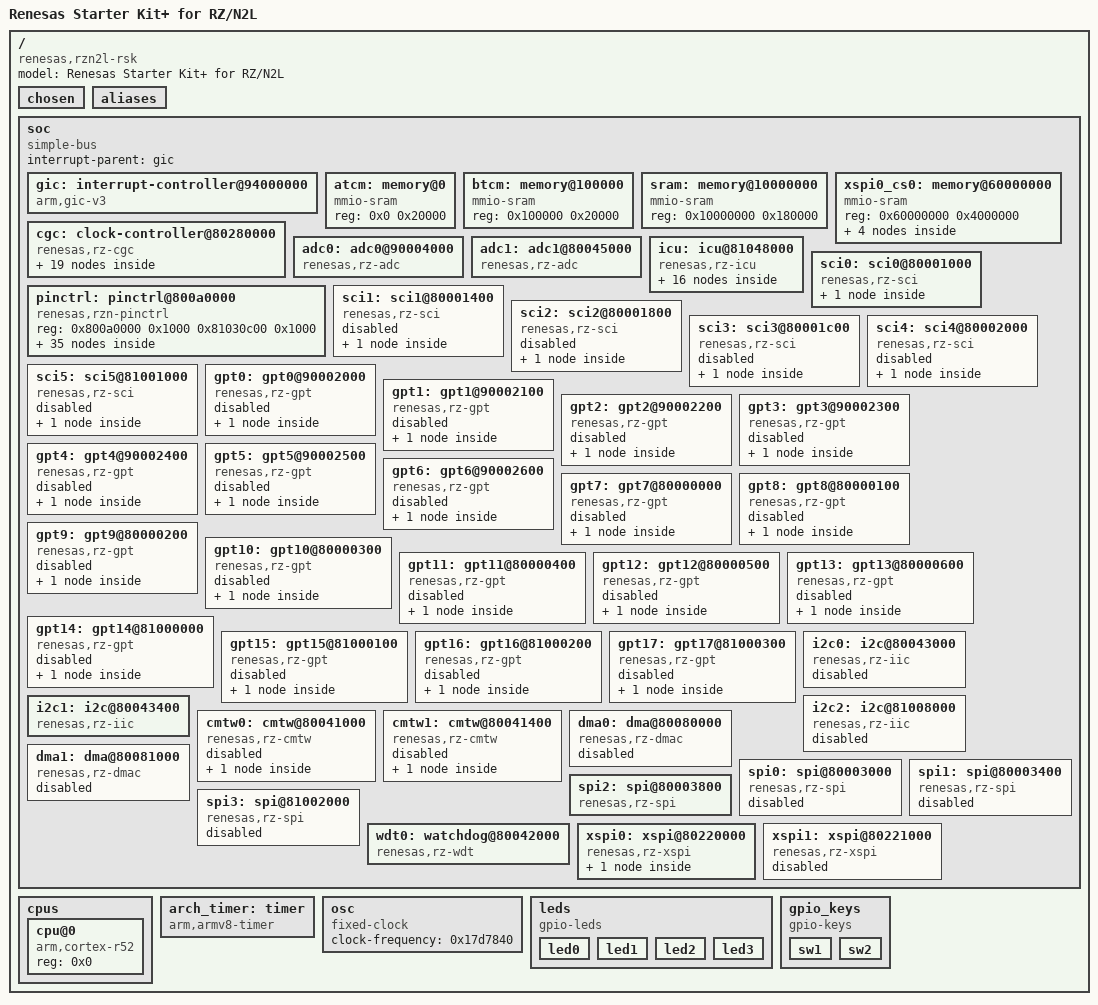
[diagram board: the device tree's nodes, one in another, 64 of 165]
/dts-v1/;

/* node '/' defined in zephyr/dts/common/skeleton.dtsi:9 */
/ {
	#address-cells = < 0x1 >;                  /* in zephyr/dts/arm/renesas/rz/rzn/r9a07g084.dtsi:16 */
	#size-cells = < 0x1 >;                     /* in zephyr/dts/arm/renesas/rz/rzn/r9a07g084.dtsi:17 */
	model = "Renesas Starter Kit+ for RZ/N2L"; /* in zephyr/boards/renesas/rzn2l_rsk/rzn2l_rsk.dts:12 */
	compatible = "renesas,rzn2l-rsk";          /* in zephyr/boards/renesas/rzn2l_rsk/rzn2l_rsk.dts:13 */

	/* node '/chosen' defined in zephyr/dts/common/skeleton.dtsi:13 */
	chosen {
		zephyr,sram = &atcm;                      /* in zephyr/boards/renesas/rzn2l_rsk/rzn2l_rsk.dts:16 */
		zephyr,flash = &mx25u51245g;              /* in zephyr/boards/renesas/rzn2l_rsk/rzn2l_rsk.dts:17 */
		zephyr,code-partition = &slot0_partition; /* in zephyr/boards/renesas/rzn2l_rsk/rzn2l_rsk.dts:18 */
		zephyr,console = &uart0;                  /* in zephyr/boards/renesas/rzn2l_rsk/rzn2l_rsk.dts:19 */
		zephyr,shell-uart = &uart0;               /* in zephyr/boards/renesas/rzn2l_rsk/rzn2l_rsk.dts:20 */
	};

	/* node '/aliases' defined in zephyr/dts/common/skeleton.dtsi:15 */
	aliases {
		led0 = &led0;      /* in zephyr/boards/renesas/rzn2l_rsk/rzn2l_rsk.dts:24 */
		led1 = &led1;      /* in zephyr/boards/renesas/rzn2l_rsk/rzn2l_rsk.dts:25 */
		sw0 = &sw1;        /* in zephyr/boards/renesas/rzn2l_rsk/rzn2l_rsk.dts:26 */
		watchdog0 = &wdt0; /* in zephyr/boards/renesas/rzn2l_rsk/rzn2l_rsk.dts:27 */
	};

	/* node '/soc' defined in zephyr/dts/arm/armv8-r.dtsi:10 */
	soc {
		#address-cells = < 0x1 >;    /* in zephyr/dts/arm/armv8-r.dtsi:11 */
		#size-cells = < 0x1 >;       /* in zephyr/dts/arm/armv8-r.dtsi:12 */
		compatible = "simple-bus";   /* in zephyr/dts/arm/armv8-r.dtsi:13 */
		ranges;                      /* in zephyr/dts/arm/armv8-r.dtsi:14 */
		interrupt-parent = < &gic >; /* in zephyr/dts/arm/renesas/rz/rzn/r9a07g084.dtsi:47 */

		/* node '/soc/interrupt-controller@94000000' defined in zephyr/dts/arm/renesas/rz/rzn/r9a07g084.dtsi:49 */
		gic: interrupt-controller@94000000 {
			compatible = "arm,gic-v3",
			             "arm,gic";       /* in zephyr/dts/arm/renesas/rz/rzn/r9a07g084.dtsi:50 */
			reg = < 0x94000000 0x10000 >,
			      < 0x94100000 0x80000 >; /* in zephyr/dts/arm/renesas/rz/rzn/r9a07g084.dtsi:51 */
			interrupt-controller;         /* in zephyr/dts/arm/renesas/rz/rzn/r9a07g084.dtsi:53 */
			#interrupt-cells = < 0x4 >;   /* in zephyr/dts/arm/renesas/rz/rzn/r9a07g084.dtsi:54 */
			status = "okay";              /* in zephyr/dts/arm/renesas/rz/rzn/r9a07g084.dtsi:55 */
			phandle = < 0x1 >;            /* in zephyr/dts/arm/renesas/rz/rzn/r9a07g084.dtsi:47 */
		};

		/* node '/soc/memory@0' defined in zephyr/dts/arm/renesas/rz/rzn/r9a07g084.dtsi:58 */
		atcm: memory@0 {
			compatible = "mmio-sram"; /* in zephyr/dts/arm/renesas/rz/rzn/r9a07g084.dtsi:59 */
			reg = < 0x0 0x20000 >;    /* in zephyr/dts/arm/renesas/rz/rzn/r9a07g084.dtsi:60 */
		};

		/* node '/soc/memory@100000' defined in zephyr/dts/arm/renesas/rz/rzn/r9a07g084.dtsi:63 */
		btcm: memory@100000 {
			compatible = "mmio-sram";   /* in zephyr/dts/arm/renesas/rz/rzn/r9a07g084.dtsi:64 */
			reg = < 0x100000 0x20000 >; /* in zephyr/dts/arm/renesas/rz/rzn/r9a07g084.dtsi:65 */
		};

		/* node '/soc/memory@10000000' defined in zephyr/dts/arm/renesas/rz/rzn/r9a07g084.dtsi:68 */
		sram: memory@10000000 {
			compatible = "mmio-sram";      /* in zephyr/dts/arm/renesas/rz/rzn/r9a07g084.dtsi:69 */
			reg = < 0x10000000 0x180000 >; /* in zephyr/dts/arm/renesas/rz/rzn/r9a07g084.dtsi:70 */
		};

		/* node '/soc/memory@60000000' defined in zephyr/dts/arm/renesas/rz/rzn/r9a07g084.dtsi:73 */
		xspi0_cs0: memory@60000000 {
			compatible = "mmio-sram";       /* in zephyr/dts/arm/renesas/rz/rzn/r9a07g084.dtsi:74 */
			reg = < 0x60000000 0x4000000 >; /* in zephyr/dts/arm/renesas/rz/rzn/r9a07g084.dtsi:75 */

			/* node '/soc/memory@60000000/partitions' defined in zephyr/dts/arm/renesas/rz/rzn/r9a07g084.dtsi:77 */
			partitions {
				compatible = "fixed-partitions"; /* in zephyr/dts/arm/renesas/rz/rzn/r9a07g084.dtsi:78 */
				#address-cells = < 0x1 >;        /* in zephyr/dts/arm/renesas/rz/rzn/r9a07g084.dtsi:79 */
				#size-cells = < 0x1 >;           /* in zephyr/dts/arm/renesas/rz/rzn/r9a07g084.dtsi:80 */

				/* node '/soc/memory@60000000/partitions/partition@0' defined in zephyr/dts/arm/renesas/rz/rzn/r9a07g084.dtsi:82 */
				loader_param: partition@0 {
					label = "loader-param"; /* in zephyr/dts/arm/renesas/rz/rzn/r9a07g084.dtsi:83 */
					reg = < 0x0 0x4c >;     /* in zephyr/dts/arm/renesas/rz/rzn/r9a07g084.dtsi:84 */
					read-only;              /* in zephyr/dts/arm/renesas/rz/rzn/r9a07g084.dtsi:85 */
				};

				/* node '/soc/memory@60000000/partitions/partition@4C' defined in zephyr/dts/arm/renesas/rz/rzn/r9a07g084.dtsi:88 */
				loader_program: partition@4C {
					label = "loader-program"; /* in zephyr/dts/arm/renesas/rz/rzn/r9a07g084.dtsi:89 */
					reg = < 0x4c 0xdfb4 >;    /* in zephyr/dts/arm/renesas/rz/rzn/r9a07g084.dtsi:90 */
					read-only;                /* in zephyr/dts/arm/renesas/rz/rzn/r9a07g084.dtsi:91 */
				};

				/* node '/soc/memory@60000000/partitions/partition@E000' defined in zephyr/dts/arm/renesas/rz/rzn/r9a07g084.dtsi:94 */
				slot0_partition: partition@E000 {
					label = "image-0";          /* in zephyr/dts/arm/renesas/rz/rzn/r9a07g084.dtsi:95 */
					reg = < 0xe000 0x3ff2000 >; /* in zephyr/dts/arm/renesas/rz/rzn/r9a07g084.dtsi:96 */
					read-only;                  /* in zephyr/dts/arm/renesas/rz/rzn/r9a07g084.dtsi:97 */
				};
			};
		};

		/* node '/soc/clock-controller@80280000' defined in zephyr/dts/arm/renesas/rz/rzn/r9a07g084.dtsi:102 */
		cgc: clock-controller@80280000 {
			compatible = "renesas,rz-cgc"; /* in zephyr/dts/arm/renesas/rz/rzn/r9a07g084.dtsi:103 */
			reg = < 0x80280000 0x314 >,
			      < 0x81280000 0x324 >;    /* in zephyr/dts/arm/renesas/rz/rzn/r9a07g084.dtsi:104 */
			clocks = < &osc >;             /* in zephyr/dts/arm/renesas/rz/rzn/r9a07g084.dtsi:105 */
			#clock-cells = < 0x1 >;        /* in zephyr/dts/arm/renesas/rz/rzn/r9a07g084.dtsi:106 */
			status = "okay";               /* in zephyr/dts/arm/renesas/rz/rzn/r9a07g084.dtsi:107 */

			/* node '/soc/clock-controller@80280000/loco' defined in zephyr/dts/arm/renesas/rz/rzn/r9a07g084.dtsi:109 */
			loco: loco {
				compatible = "fixed-clock";    /* in zephyr/dts/arm/renesas/rz/rzn/r9a07g084.dtsi:110 */
				clock-frequency = < 0x3a980 >; /* in zephyr/dts/arm/renesas/rz/rzn/r9a07g084.dtsi:111 */
				#clock-cells = < 0x0 >;        /* in zephyr/dts/arm/renesas/rz/rzn/r9a07g084.dtsi:112 */
				status = "okay";               /* in zephyr/dts/arm/renesas/rz/rzn/r9a07g084.dtsi:113 */
			};

			/* node '/soc/clock-controller@80280000/pll1' defined in zephyr/dts/arm/renesas/rz/rzn/r9a07g084.dtsi:116 */
			pll1: pll1 {
				compatible = "renesas,rz-cgc-pll"; /* in zephyr/dts/arm/renesas/rz/rzn/r9a07g084.dtsi:117 */
				state = "initial";                 /* in zephyr/dts/arm/renesas/rz/rzn/r9a07g084.dtsi:118 */
			};

			/* node '/soc/clock-controller@80280000/iclk' defined in zephyr/dts/arm/renesas/rz/rzn/r9a07g084.dtsi:121 */
			iclk: iclk {
				compatible = "renesas,rz-cgc-sys-clock"; /* in zephyr/dts/arm/renesas/rz/rzn/r9a07g084.dtsi:122 */
				clock-frequency = < 0xbebc200 >;         /* in zephyr/dts/arm/renesas/rz/rzn/r9a07g084.dtsi:123 */

				/* node '/soc/clock-controller@80280000/iclk/cpu0clk' defined in zephyr/dts/arm/renesas/rz/rzn/r9a07g084.dtsi:125 */
				cpu0clk: cpu0clk {
					compatible = "renesas,rz-cgc-sys-clock"; /* in zephyr/dts/arm/renesas/rz/rzn/r9a07g084.dtsi:126 */
					mul = < 0x1 >;                           /* in zephyr/dts/arm/renesas/rz/rzn/r9a07g084.dtsi:127 */
				};

				/* node '/soc/clock-controller@80280000/iclk/ckio' defined in zephyr/dts/arm/renesas/rz/rzn/r9a07g084.dtsi:130 */
				ckio: ckio {
					compatible = "renesas,rz-cgc-sys-clock"; /* in zephyr/dts/arm/renesas/rz/rzn/r9a07g084.dtsi:131 */
					div = < 0x4 >;                           /* in zephyr/dts/arm/renesas/rz/rzn/r9a07g084.dtsi:132 */
				};
			};

			/* node '/soc/clock-controller@80280000/eth_refclk' defined in zephyr/dts/arm/renesas/rz/rzn/r9a07g084.dtsi:136 */
			eth_refclk: eth_refclk {
				compatible = "renesas,rz-cgc-subclk"; /* in zephyr/dts/arm/renesas/rz/rzn/r9a07g084.dtsi:137 */
				eth-phy-source = "main";              /* in zephyr/dts/arm/renesas/rz/rzn/r9a07g084.dtsi:138 */
			};

			/* node '/soc/clock-controller@80280000/canfdclk' defined in zephyr/dts/arm/renesas/rz/rzn/r9a07g084.dtsi:141 */
			canfdclk: canfdclk {
				compatible = "renesas,rz-cgc-subclk"; /* in zephyr/dts/arm/renesas/rz/rzn/r9a07g084.dtsi:142 */
				canfd-source = < 0x1 >;               /* in zephyr/dts/arm/renesas/rz/rzn/r9a07g084.dtsi:143 */
			};

			/* node '/soc/clock-controller@80280000/xspi_clk0' defined in zephyr/dts/arm/renesas/rz/rzn/r9a07g084.dtsi:146 */
			xspi_clk0: xspi_clk0 {
				compatible = "renesas,rz-cgc-subclk"; /* in zephyr/dts/arm/renesas/rz/rzn/r9a07g084.dtsi:147 */
				xspi-clk-frequency = < 0xbebc20 >;    /* in zephyr/dts/arm/renesas/rz/rzn/r9a07g084.dtsi:148 */
			};

			/* node '/soc/clock-controller@80280000/xspi_clk1' defined in zephyr/dts/arm/renesas/rz/rzn/r9a07g084.dtsi:151 */
			xspi_clk1: xspi_clk1 {
				compatible = "renesas,rz-cgc-subclk"; /* in zephyr/dts/arm/renesas/rz/rzn/r9a07g084.dtsi:152 */
				xspi-clk-frequency = < 0xbebc20 >;    /* in zephyr/dts/arm/renesas/rz/rzn/r9a07g084.dtsi:153 */
			};

			/* node '/soc/clock-controller@80280000/sci0asyncclk' defined in zephyr/dts/arm/renesas/rz/rzn/r9a07g084.dtsi:156 */
			sci0asyncclk: sci0asyncclk {
				compatible = "renesas,rz-cgc-subclk"; /* in zephyr/dts/arm/renesas/rz/rzn/r9a07g084.dtsi:157 */
				clock-frequency = < 0x5b8d800 >;      /* in zephyr/dts/arm/renesas/rz/rzn/r9a07g084.dtsi:158 */
			};

			/* node '/soc/clock-controller@80280000/sci1asyncclk' defined in zephyr/dts/arm/renesas/rz/rzn/r9a07g084.dtsi:161 */
			sci1asyncclk: sci1asyncclk {
				compatible = "renesas,rz-cgc-subclk"; /* in zephyr/dts/arm/renesas/rz/rzn/r9a07g084.dtsi:162 */
				clock-frequency = < 0x5b8d800 >;      /* in zephyr/dts/arm/renesas/rz/rzn/r9a07g084.dtsi:163 */
			};

			/* node '/soc/clock-controller@80280000/sci2asyncclk' defined in zephyr/dts/arm/renesas/rz/rzn/r9a07g084.dtsi:166 */
			sci2asyncclk: sci2asyncclk {
				compatible = "renesas,rz-cgc-subclk"; /* in zephyr/dts/arm/renesas/rz/rzn/r9a07g084.dtsi:167 */
				clock-frequency = < 0x5b8d800 >;      /* in zephyr/dts/arm/renesas/rz/rzn/r9a07g084.dtsi:168 */
			};

			/* node '/soc/clock-controller@80280000/sci3asyncclk' defined in zephyr/dts/arm/renesas/rz/rzn/r9a07g084.dtsi:171 */
			sci3asyncclk: sci3asyncclk {
				compatible = "renesas,rz-cgc-subclk"; /* in zephyr/dts/arm/renesas/rz/rzn/r9a07g084.dtsi:172 */
				clock-frequency = < 0x5b8d800 >;      /* in zephyr/dts/arm/renesas/rz/rzn/r9a07g084.dtsi:173 */
			};

			/* node '/soc/clock-controller@80280000/sci4asyncclk' defined in zephyr/dts/arm/renesas/rz/rzn/r9a07g084.dtsi:176 */
			sci4asyncclk: sci4asyncclk {
				compatible = "renesas,rz-cgc-subclk"; /* in zephyr/dts/arm/renesas/rz/rzn/r9a07g084.dtsi:177 */
				clock-frequency = < 0x5b8d800 >;      /* in zephyr/dts/arm/renesas/rz/rzn/r9a07g084.dtsi:178 */
			};

			/* node '/soc/clock-controller@80280000/sci5asyncclk' defined in zephyr/dts/arm/renesas/rz/rzn/r9a07g084.dtsi:181 */
			sci5asyncclk: sci5asyncclk {
				compatible = "renesas,rz-cgc-subclk"; /* in zephyr/dts/arm/renesas/rz/rzn/r9a07g084.dtsi:182 */
				clock-frequency = < 0x5b8d800 >;      /* in zephyr/dts/arm/renesas/rz/rzn/r9a07g084.dtsi:183 */
			};

			/* node '/soc/clock-controller@80280000/spi0asyncclk' defined in zephyr/dts/arm/renesas/rz/rzn/r9a07g084.dtsi:186 */
			spi0asyncclk: spi0asyncclk {
				compatible = "renesas,rz-cgc-subclk"; /* in zephyr/dts/arm/renesas/rz/rzn/r9a07g084.dtsi:187 */
				clock-frequency = < 0x5b8d800 >;      /* in zephyr/dts/arm/renesas/rz/rzn/r9a07g084.dtsi:188 */
			};

			/* node '/soc/clock-controller@80280000/spi1asyncclk' defined in zephyr/dts/arm/renesas/rz/rzn/r9a07g084.dtsi:191 */
			spi1asyncclk: spi1asyncclk {
				compatible = "renesas,rz-cgc-subclk"; /* in zephyr/dts/arm/renesas/rz/rzn/r9a07g084.dtsi:192 */
				clock-frequency = < 0x5b8d800 >;      /* in zephyr/dts/arm/renesas/rz/rzn/r9a07g084.dtsi:193 */
			};

			/* node '/soc/clock-controller@80280000/spi2asyncclk' defined in zephyr/dts/arm/renesas/rz/rzn/r9a07g084.dtsi:196 */
			spi2asyncclk: spi2asyncclk {
				compatible = "renesas,rz-cgc-subclk"; /* in zephyr/dts/arm/renesas/rz/rzn/r9a07g084.dtsi:197 */
				clock-frequency = < 0x5b8d800 >;      /* in zephyr/dts/arm/renesas/rz/rzn/r9a07g084.dtsi:198 */
			};

			/* node '/soc/clock-controller@80280000/spi3asyncclk' defined in zephyr/dts/arm/renesas/rz/rzn/r9a07g084.dtsi:201 */
			spi3asyncclk: spi3asyncclk {
				compatible = "renesas,rz-cgc-subclk"; /* in zephyr/dts/arm/renesas/rz/rzn/r9a07g084.dtsi:202 */
				clock-frequency = < 0x5b8d800 >;      /* in zephyr/dts/arm/renesas/rz/rzn/r9a07g084.dtsi:203 */
			};
		};

		/* node '/soc/adc0@90004000' defined in zephyr/dts/arm/renesas/rz/rzn/r9a07g084.dtsi:207 */
		adc0: adc0@90004000 {
			compatible = "renesas,rz-adc";       /* in zephyr/dts/arm/renesas/rz/rzn/r9a07g084.dtsi:208 */
			reg = < 0x90004000 0x1000 >;         /* in zephyr/dts/arm/renesas/rz/rzn/r9a07g084.dtsi:209 */
			unit = < 0x0 >;                      /* in zephyr/dts/arm/renesas/rz/rzn/r9a07g084.dtsi:210 */
			interrupts = < 0x0 0x159 0x4 0xa0 >; /* in zephyr/dts/arm/renesas/rz/rzn/r9a07g084.dtsi:211 */
			interrupt-names = "scanend";         /* in zephyr/dts/arm/renesas/rz/rzn/r9a07g084.dtsi:212 */
			#io-channel-cells = < 0x1 >;         /* in zephyr/dts/arm/renesas/rz/rzn/r9a07g084.dtsi:213 */
			vref-mv = < 0x708 >;                 /* in zephyr/dts/arm/renesas/rz/rzn/r9a07g084.dtsi:214 */
			channel-available-mask = < 0xf >;    /* in zephyr/dts/arm/renesas/rz/rzn/r9a07g084.dtsi:215 */
			status = "okay";                     /* in zephyr/boards/renesas/rzn2l_rsk/rzn2l_rsk.dts:115 */
		};

		/* node '/soc/adc1@80045000' defined in zephyr/dts/arm/renesas/rz/rzn/r9a07g084.dtsi:219 */
		adc1: adc1@80045000 {
			compatible = "renesas,rz-adc";       /* in zephyr/dts/arm/renesas/rz/rzn/r9a07g084.dtsi:220 */
			reg = < 0x80045000 0x1000 >;         /* in zephyr/dts/arm/renesas/rz/rzn/r9a07g084.dtsi:221 */
			unit = < 0x1 >;                      /* in zephyr/dts/arm/renesas/rz/rzn/r9a07g084.dtsi:222 */
			interrupts = < 0x0 0x15e 0x4 0xa0 >; /* in zephyr/dts/arm/renesas/rz/rzn/r9a07g084.dtsi:223 */
			interrupt-names = "scanend";         /* in zephyr/dts/arm/renesas/rz/rzn/r9a07g084.dtsi:224 */
			#io-channel-cells = < 0x1 >;         /* in zephyr/dts/arm/renesas/rz/rzn/r9a07g084.dtsi:225 */
			vref-mv = < 0x708 >;                 /* in zephyr/dts/arm/renesas/rz/rzn/r9a07g084.dtsi:226 */
			channel-available-mask = < 0xff >;   /* in zephyr/dts/arm/renesas/rz/rzn/r9a07g084.dtsi:227 */
			status = "okay";                     /* in zephyr/boards/renesas/rzn2l_rsk/rzn2l_rsk.dts:119 */
		};

		/* node '/soc/icu@81048000' defined in zephyr/dts/arm/renesas/rz/rzn/r9a07g084.dtsi:231 */
		icu: icu@81048000 {
			compatible = "renesas,rz-icu"; /* in zephyr/dts/arm/renesas/rz/rzn/r9a07g084.dtsi:232 */
			reg = < 0x81048000 0x1000 >;   /* in zephyr/dts/arm/renesas/rz/rzn/r9a07g084.dtsi:233 */
			interrupt-parent = < &gic >;   /* in zephyr/dts/arm/renesas/rz/rzn/r9a07g084.dtsi:234 */
			#address-cells = < 0x1 >;      /* in zephyr/dts/arm/renesas/rz/rzn/r9a07g084.dtsi:235 */
			#size-cells = < 0x0 >;         /* in zephyr/dts/arm/renesas/rz/rzn/r9a07g084.dtsi:236 */

			/* node '/soc/icu@81048000/irq0@0' defined in zephyr/dts/arm/renesas/rz/rzn/r9a07g084.dtsi:238 */
			irq0: irq0@0 {
				compatible = "renesas,rz-ext-irq"; /* in zephyr/dts/arm/renesas/rz/rzn/r9a07g084.dtsi:239 */
				reg = < 0x0 >;                     /* in zephyr/dts/arm/renesas/rz/rzn/r9a07g084.dtsi:240 */
				interrupts = < 0x0 0x6 0x4 0xa0 >; /* in zephyr/dts/arm/renesas/rz/rzn/r9a07g084.dtsi:241 */
				interrupt-controller;              /* in zephyr/dts/arm/renesas/rz/rzn/r9a07g084.dtsi:242 */
				#interrupt-cells = < 0x2 >;        /* in zephyr/dts/arm/renesas/rz/rzn/r9a07g084.dtsi:243 */
				status = "disabled";               /* in zephyr/dts/arm/renesas/rz/rzn/r9a07g084.dtsi:244 */
			};

			/* node '/soc/icu@81048000/irq@1' defined in zephyr/dts/arm/renesas/rz/rzn/r9a07g084.dtsi:247 */
			irq1: irq@1 {
				compatible = "renesas,rz-ext-irq"; /* in zephyr/dts/arm/renesas/rz/rzn/r9a07g084.dtsi:248 */
				reg = < 0x1 >;                     /* in zephyr/dts/arm/renesas/rz/rzn/r9a07g084.dtsi:249 */
				interrupts = < 0x0 0x7 0x4 0xa0 >; /* in zephyr/dts/arm/renesas/rz/rzn/r9a07g084.dtsi:250 */
				interrupt-controller;              /* in zephyr/dts/arm/renesas/rz/rzn/r9a07g084.dtsi:251 */
				#interrupt-cells = < 0x2 >;        /* in zephyr/dts/arm/renesas/rz/rzn/r9a07g084.dtsi:252 */
				status = "disabled";               /* in zephyr/dts/arm/renesas/rz/rzn/r9a07g084.dtsi:253 */
			};

			/* node '/soc/icu@81048000/irq@2' defined in zephyr/dts/arm/renesas/rz/rzn/r9a07g084.dtsi:256 */
			irq2: irq@2 {
				compatible = "renesas,rz-ext-irq"; /* in zephyr/dts/arm/renesas/rz/rzn/r9a07g084.dtsi:257 */
				reg = < 0x2 >;                     /* in zephyr/dts/arm/renesas/rz/rzn/r9a07g084.dtsi:258 */
				interrupts = < 0x0 0x8 0x4 0xa0 >; /* in zephyr/dts/arm/renesas/rz/rzn/r9a07g084.dtsi:259 */
				interrupt-controller;              /* in zephyr/dts/arm/renesas/rz/rzn/r9a07g084.dtsi:260 */
				#interrupt-cells = < 0x2 >;        /* in zephyr/dts/arm/renesas/rz/rzn/r9a07g084.dtsi:261 */
				status = "disabled";               /* in zephyr/dts/arm/renesas/rz/rzn/r9a07g084.dtsi:262 */
			};

			/* node '/soc/icu@81048000/irq@3' defined in zephyr/dts/arm/renesas/rz/rzn/r9a07g084.dtsi:265 */
			irq3: irq@3 {
				compatible = "renesas,rz-ext-irq"; /* in zephyr/dts/arm/renesas/rz/rzn/r9a07g084.dtsi:266 */
				reg = < 0x3 >;                     /* in zephyr/dts/arm/renesas/rz/rzn/r9a07g084.dtsi:267 */
				interrupts = < 0x0 0x9 0x4 0xa0 >; /* in zephyr/dts/arm/renesas/rz/rzn/r9a07g084.dtsi:268 */
				interrupt-controller;              /* in zephyr/dts/arm/renesas/rz/rzn/r9a07g084.dtsi:269 */
				#interrupt-cells = < 0x2 >;        /* in zephyr/dts/arm/renesas/rz/rzn/r9a07g084.dtsi:270 */
				status = "disabled";               /* in zephyr/dts/arm/renesas/rz/rzn/r9a07g084.dtsi:271 */
			};

			/* node '/soc/icu@81048000/irq@4' defined in zephyr/dts/arm/renesas/rz/rzn/r9a07g084.dtsi:274 */
			irq4: irq@4 {
				compatible = "renesas,rz-ext-irq"; /* in zephyr/dts/arm/renesas/rz/rzn/r9a07g084.dtsi:275 */
				reg = < 0x4 >;                     /* in zephyr/dts/arm/renesas/rz/rzn/r9a07g084.dtsi:276 */
				interrupts = < 0x0 0xa 0x4 0xa0 >; /* in zephyr/dts/arm/renesas/rz/rzn/r9a07g084.dtsi:277 */
				interrupt-controller;              /* in zephyr/dts/arm/renesas/rz/rzn/r9a07g084.dtsi:278 */
				#interrupt-cells = < 0x2 >;        /* in zephyr/dts/arm/renesas/rz/rzn/r9a07g084.dtsi:279 */
				status = "disabled";               /* in zephyr/dts/arm/renesas/rz/rzn/r9a07g084.dtsi:280 */
			};

			/* node '/soc/icu@81048000/irq@5' defined in zephyr/dts/arm/renesas/rz/rzn/r9a07g084.dtsi:283 */
			irq5: irq@5 {
				compatible = "renesas,rz-ext-irq"; /* in zephyr/dts/arm/renesas/rz/rzn/r9a07g084.dtsi:284 */
				reg = < 0x5 >;                     /* in zephyr/dts/arm/renesas/rz/rzn/r9a07g084.dtsi:285 */
				interrupts = < 0x0 0xb 0x4 0xa0 >; /* in zephyr/dts/arm/renesas/rz/rzn/r9a07g084.dtsi:286 */
				interrupt-controller;              /* in zephyr/dts/arm/renesas/rz/rzn/r9a07g084.dtsi:287 */
				#interrupt-cells = < 0x2 >;        /* in zephyr/dts/arm/renesas/rz/rzn/r9a07g084.dtsi:288 */
				status = "disabled";               /* in zephyr/dts/arm/renesas/rz/rzn/r9a07g084.dtsi:289 */
			};

			/* node '/soc/icu@81048000/irq@6' defined in zephyr/dts/arm/renesas/rz/rzn/r9a07g084.dtsi:292 */
			irq6: irq@6 {
				compatible = "renesas,rz-ext-irq"; /* in zephyr/dts/arm/renesas/rz/rzn/r9a07g084.dtsi:293 */
				reg = < 0x6 >;                     /* in zephyr/dts/arm/renesas/rz/rzn/r9a07g084.dtsi:294 */
				interrupts = < 0x0 0xc 0x4 0xa0 >; /* in zephyr/dts/arm/renesas/rz/rzn/r9a07g084.dtsi:295 */
				interrupt-controller;              /* in zephyr/dts/arm/renesas/rz/rzn/r9a07g084.dtsi:296 */
				#interrupt-cells = < 0x2 >;        /* in zephyr/dts/arm/renesas/rz/rzn/r9a07g084.dtsi:297 */
				status = "disabled";               /* in zephyr/dts/arm/renesas/rz/rzn/r9a07g084.dtsi:298 */
			};

			/* node '/soc/icu@81048000/irq@7' defined in zephyr/dts/arm/renesas/rz/rzn/r9a07g084.dtsi:301 */
			irq7: irq@7 {
				compatible = "renesas,rz-ext-irq"; /* in zephyr/dts/arm/renesas/rz/rzn/r9a07g084.dtsi:302 */
				reg = < 0x7 >;                     /* in zephyr/dts/arm/renesas/rz/rzn/r9a07g084.dtsi:303 */
				interrupts = < 0x0 0xd 0x4 0xa0 >; /* in zephyr/dts/arm/renesas/rz/rzn/r9a07g084.dtsi:304 */
				interrupt-controller;              /* in zephyr/dts/arm/renesas/rz/rzn/r9a07g084.dtsi:305 */
				#interrupt-cells = < 0x2 >;        /* in zephyr/dts/arm/renesas/rz/rzn/r9a07g084.dtsi:306 */
				trigger-type = "falling";          /* in zephyr/boards/renesas/rzn2l_rsk/rzn2l_rsk.dts:99 */
				pinctrl-0 = < &irq7_default >;     /* in zephyr/boards/renesas/rzn2l_rsk/rzn2l_rsk.dts:100 */
				pinctrl-names = "default";         /* in zephyr/boards/renesas/rzn2l_rsk/rzn2l_rsk.dts:101 */
				status = "okay";                   /* in zephyr/boards/renesas/rzn2l_rsk/rzn2l_rsk.dts:102 */
			};

			/* node '/soc/icu@81048000/irq@8' defined in zephyr/dts/arm/renesas/rz/rzn/r9a07g084.dtsi:310 */
			irq8: irq@8 {
				compatible = "renesas,rz-ext-irq"; /* in zephyr/dts/arm/renesas/rz/rzn/r9a07g084.dtsi:311 */
				reg = < 0x8 >;                     /* in zephyr/dts/arm/renesas/rz/rzn/r9a07g084.dtsi:312 */
				interrupts = < 0x0 0xe 0x4 0xa0 >; /* in zephyr/dts/arm/renesas/rz/rzn/r9a07g084.dtsi:313 */
				interrupt-controller;              /* in zephyr/dts/arm/renesas/rz/rzn/r9a07g084.dtsi:314 */
				#interrupt-cells = < 0x2 >;        /* in zephyr/dts/arm/renesas/rz/rzn/r9a07g084.dtsi:315 */
				status = "disabled";               /* in zephyr/dts/arm/renesas/rz/rzn/r9a07g084.dtsi:316 */
			};

			/* node '/soc/icu@81048000/irq@9' defined in zephyr/dts/arm/renesas/rz/rzn/r9a07g084.dtsi:319 */
			irq9: irq@9 {
				compatible = "renesas,rz-ext-irq"; /* in zephyr/dts/arm/renesas/rz/rzn/r9a07g084.dtsi:320 */
				reg = < 0x9 >;                     /* in zephyr/dts/arm/renesas/rz/rzn/r9a07g084.dtsi:321 */
				interrupts = < 0x0 0xf 0x4 0xa0 >; /* in zephyr/dts/arm/renesas/rz/rzn/r9a07g084.dtsi:322 */
				interrupt-controller;              /* in zephyr/dts/arm/renesas/rz/rzn/r9a07g084.dtsi:323 */
				#interrupt-cells = < 0x2 >;        /* in zephyr/dts/arm/renesas/rz/rzn/r9a07g084.dtsi:324 */
				status = "disabled";               /* in zephyr/dts/arm/renesas/rz/rzn/r9a07g084.dtsi:325 */
			};

			/* node '/soc/icu@81048000/irq@a' defined in zephyr/dts/arm/renesas/rz/rzn/r9a07g084.dtsi:328 */
			irq10: irq@a {
				compatible = "renesas,rz-ext-irq";  /* in zephyr/dts/arm/renesas/rz/rzn/r9a07g084.dtsi:329 */
				reg = < 0xa >;                      /* in zephyr/dts/arm/renesas/rz/rzn/r9a07g084.dtsi:330 */
				interrupts = < 0x0 0x10 0x4 0xa0 >; /* in zephyr/dts/arm/renesas/rz/rzn/r9a07g084.dtsi:331 */
				interrupt-controller;               /* in zephyr/dts/arm/renesas/rz/rzn/r9a07g084.dtsi:332 */
				#interrupt-cells = < 0x2 >;         /* in zephyr/dts/arm/renesas/rz/rzn/r9a07g084.dtsi:333 */
				status = "disabled";                /* in zephyr/dts/arm/renesas/rz/rzn/r9a07g084.dtsi:334 */
			};

			/* node '/soc/icu@81048000/irq@b' defined in zephyr/dts/arm/renesas/rz/rzn/r9a07g084.dtsi:337 */
			irq11: irq@b {
				compatible = "renesas,rz-ext-irq";  /* in zephyr/dts/arm/renesas/rz/rzn/r9a07g084.dtsi:338 */
				reg = < 0xb >;                      /* in zephyr/dts/arm/renesas/rz/rzn/r9a07g084.dtsi:339 */
				interrupts = < 0x0 0x11 0x4 0xa0 >; /* in zephyr/dts/arm/renesas/rz/rzn/r9a07g084.dtsi:340 */
				interrupt-controller;               /* in zephyr/dts/arm/renesas/rz/rzn/r9a07g084.dtsi:341 */
				#interrupt-cells = < 0x2 >;         /* in zephyr/dts/arm/renesas/rz/rzn/r9a07g084.dtsi:342 */
				status = "disabled";                /* in zephyr/dts/arm/renesas/rz/rzn/r9a07g084.dtsi:343 */
			};

			/* node '/soc/icu@81048000/irq@c' defined in zephyr/dts/arm/renesas/rz/rzn/r9a07g084.dtsi:346 */
			irq12: irq@c {
				compatible = "renesas,rz-ext-irq";  /* in zephyr/dts/arm/renesas/rz/rzn/r9a07g084.dtsi:347 */
				reg = < 0xc >;                      /* in zephyr/dts/arm/renesas/rz/rzn/r9a07g084.dtsi:348 */
				interrupts = < 0x0 0x12 0x4 0xa0 >; /* in zephyr/dts/arm/renesas/rz/rzn/r9a07g084.dtsi:349 */
				interrupt-controller;               /* in zephyr/dts/arm/renesas/rz/rzn/r9a07g084.dtsi:350 */
				#interrupt-cells = < 0x2 >;         /* in zephyr/dts/arm/renesas/rz/rzn/r9a07g084.dtsi:351 */
				status = "disabled";                /* in zephyr/dts/arm/renesas/rz/rzn/r9a07g084.dtsi:352 */
			};

			/* node '/soc/icu@81048000/irq@d' defined in zephyr/dts/arm/renesas/rz/rzn/r9a07g084.dtsi:355 */
			irq13: irq@d {
				compatible = "renesas,rz-ext-irq";  /* in zephyr/dts/arm/renesas/rz/rzn/r9a07g084.dtsi:356 */
				reg = < 0xd >;                      /* in zephyr/dts/arm/renesas/rz/rzn/r9a07g084.dtsi:357 */
				interrupts = < 0x0 0x13 0x4 0xa0 >; /* in zephyr/dts/arm/renesas/rz/rzn/r9a07g084.dtsi:358 */
				interrupt-controller;               /* in zephyr/dts/arm/renesas/rz/rzn/r9a07g084.dtsi:359 */
				#interrupt-cells = < 0x2 >;         /* in zephyr/dts/arm/renesas/rz/rzn/r9a07g084.dtsi:360 */
				status = "disabled";                /* in zephyr/dts/arm/renesas/rz/rzn/r9a07g084.dtsi:361 */
			};

			/* node '/soc/icu@81048000/irq@e' defined in zephyr/dts/arm/renesas/rz/rzn/r9a07g084.dtsi:364 */
			irq14: irq@e {
				compatible = "renesas,rz-ext-irq";   /* in zephyr/dts/arm/renesas/rz/rzn/r9a07g084.dtsi:365 */
				reg = < 0xe >;                       /* in zephyr/dts/arm/renesas/rz/rzn/r9a07g084.dtsi:366 */
				interrupts = < 0x0 0x18a 0x4 0xa0 >; /* in zephyr/dts/arm/renesas/rz/rzn/r9a07g084.dtsi:367 */
				interrupt-controller;                /* in zephyr/dts/arm/renesas/rz/rzn/r9a07g084.dtsi:368 */
				#interrupt-cells = < 0x2 >;          /* in zephyr/dts/arm/renesas/rz/rzn/r9a07g084.dtsi:369 */
				status = "disabled";                 /* in zephyr/dts/arm/renesas/rz/rzn/r9a07g084.dtsi:370 */
			};

			/* node '/soc/icu@81048000/irq@f' defined in zephyr/dts/arm/renesas/rz/rzn/r9a07g084.dtsi:373 */
			irq15: irq@f {
				compatible = "renesas,rz-ext-irq";   /* in zephyr/dts/arm/renesas/rz/rzn/r9a07g084.dtsi:374 */
				reg = < 0xf >;                       /* in zephyr/dts/arm/renesas/rz/rzn/r9a07g084.dtsi:375 */
				interrupts = < 0x0 0x18b 0x4 0xa0 >; /* in zephyr/dts/arm/renesas/rz/rzn/r9a07g084.dtsi:376 */
				interrupt-controller;                /* in zephyr/dts/arm/renesas/rz/rzn/r9a07g084.dtsi:377 */
				#interrupt-cells = < 0x2 >;          /* in zephyr/dts/arm/renesas/rz/rzn/r9a07g084.dtsi:378 */
				status = "disabled";                 /* in zephyr/dts/arm/renesas/rz/rzn/r9a07g084.dtsi:379 */
			};
		};

		/* node '/soc/pinctrl@800a0000' defined in zephyr/dts/arm/renesas/rz/rzn/r9a07g084.dtsi:383 */
		pinctrl: pinctrl@800a0000 {
			compatible = "renesas,rzn-pinctrl";            /* in zephyr/dts/arm/renesas/rz/rzn/r9a07g084.dtsi:384 */
			reg = < 0x800a0000 0x1000 0x81030c00 0x1000 >; /* in zephyr/dts/arm/renesas/rz/rzn/r9a07g084.dtsi:385 */
			#address-cells = < 0x1 >;                      /* in zephyr/dts/arm/renesas/rz/rzn/r9a07g084.dtsi:386 */
			#size-cells = < 0x0 >;                         /* in zephyr/dts/arm/renesas/rz/rzn/r9a07g084.dtsi:387 */

			/* node '/soc/pinctrl@800a0000/gpio@0' defined in zephyr/dts/arm/renesas/rz/rzn/r9a07g084.dtsi:389 */
			gpio0: gpio@0 {
				compatible = "renesas,rz-gpio"; /* in zephyr/dts/arm/renesas/rz/rzn/r9a07g084.dtsi:390 */
				gpio-controller;                /* in zephyr/dts/arm/renesas/rz/rzn/r9a07g084.dtsi:391 */
				#gpio-cells = < 0x2 >;          /* in zephyr/dts/arm/renesas/rz/rzn/r9a07g084.dtsi:392 */
				ngpios = < 0x8 >;               /* in zephyr/dts/arm/renesas/rz/rzn/r9a07g084.dtsi:393 */
				reg = < 0x0 >;                  /* in zephyr/dts/arm/renesas/rz/rzn/r9a07g084.dtsi:394 */
				status = "disabled";            /* in zephyr/dts/arm/renesas/rz/rzn/r9a07g084.dtsi:395 */
			};

			/* node '/soc/pinctrl@800a0000/gpio@100' defined in zephyr/dts/arm/renesas/rz/rzn/r9a07g084.dtsi:398 */
			gpio1: gpio@100 {
				compatible = "renesas,rz-gpio"; /* in zephyr/dts/arm/renesas/rz/rzn/r9a07g084.dtsi:399 */
				gpio-controller;                /* in zephyr/dts/arm/renesas/rz/rzn/r9a07g084.dtsi:400 */
				#gpio-cells = < 0x2 >;          /* in zephyr/dts/arm/renesas/rz/rzn/r9a07g084.dtsi:401 */
				ngpios = < 0x8 >;               /* in zephyr/dts/arm/renesas/rz/rzn/r9a07g084.dtsi:402 */
				reg = < 0x100 >;                /* in zephyr/dts/arm/renesas/rz/rzn/r9a07g084.dtsi:403 */
				status = "disabled";            /* in zephyr/dts/arm/renesas/rz/rzn/r9a07g084.dtsi:404 */
			};

			/* node '/soc/pinctrl@800a0000/gpio@200' defined in zephyr/dts/arm/renesas/rz/rzn/r9a07g084.dtsi:407 */
			gpio2: gpio@200 {
				compatible = "renesas,rz-gpio"; /* in zephyr/dts/arm/renesas/rz/rzn/r9a07g084.dtsi:408 */
				gpio-controller;                /* in zephyr/dts/arm/renesas/rz/rzn/r9a07g084.dtsi:409 */
				#gpio-cells = < 0x2 >;          /* in zephyr/dts/arm/renesas/rz/rzn/r9a07g084.dtsi:410 */
				ngpios = < 0x8 >;               /* in zephyr/dts/arm/renesas/rz/rzn/r9a07g084.dtsi:411 */
				reg = < 0x200 >;                /* in zephyr/dts/arm/renesas/rz/rzn/r9a07g084.dtsi:412 */
				status = "disabled";            /* in zephyr/dts/arm/renesas/rz/rzn/r9a07g084.dtsi:413 */
			};

			/* node '/soc/pinctrl@800a0000/gpio@300' defined in zephyr/dts/arm/renesas/rz/rzn/r9a07g084.dtsi:416 */
			gpio3: gpio@300 {
				compatible = "renesas,rz-gpio";     /* in zephyr/dts/arm/renesas/rz/rzn/r9a07g084.dtsi:417 */
				gpio-controller;                    /* in zephyr/dts/arm/renesas/rz/rzn/r9a07g084.dtsi:418 */
				#gpio-cells = < 0x2 >;              /* in zephyr/dts/arm/renesas/rz/rzn/r9a07g084.dtsi:419 */
				ngpios = < 0x8 >;                   /* in zephyr/dts/arm/renesas/rz/rzn/r9a07g084.dtsi:420 */
				gpio-reserved-ranges = < 0x1 0x4 >; /* in zephyr/dts/arm/renesas/rz/rzn/r9a07g084.dtsi:421 */
				reg = < 0x300 >;                    /* in zephyr/dts/arm/renesas/rz/rzn/r9a07g084.dtsi:422 */
				status = "disabled";                /* in zephyr/dts/arm/renesas/rz/rzn/r9a07g084.dtsi:423 */
			};

			/* node '/soc/pinctrl@800a0000/gpio@400' defined in zephyr/dts/arm/renesas/rz/rzn/r9a07g084.dtsi:426 */
			gpio4: gpio@400 {
				compatible = "renesas,rz-gpio";     /* in zephyr/dts/arm/renesas/rz/rzn/r9a07g084.dtsi:427 */
				gpio-controller;                    /* in zephyr/dts/arm/renesas/rz/rzn/r9a07g084.dtsi:428 */
				#gpio-cells = < 0x2 >;              /* in zephyr/dts/arm/renesas/rz/rzn/r9a07g084.dtsi:429 */
				ngpios = < 0x8 >;                   /* in zephyr/dts/arm/renesas/rz/rzn/r9a07g084.dtsi:430 */
				gpio-reserved-ranges = < 0x2 0x2 >; /* in zephyr/dts/arm/renesas/rz/rzn/r9a07g084.dtsi:431 */
				reg = < 0x400 >;                    /* in zephyr/dts/arm/renesas/rz/rzn/r9a07g084.dtsi:432 */
				status = "okay";                    /* in zephyr/boards/renesas/rzn2l_rsk/rzn2l_rsk.dts:91 */
				phandle = < 0xa >;                  /* in zephyr/boards/renesas/rzn2l_rsk/rzn2l_rsk.dts:44 */
			};

			/* node '/soc/pinctrl@800a0000/gpio@500' defined in zephyr/dts/arm/renesas/rz/rzn/r9a07g084.dtsi:436 */
			gpio5: gpio@500 {
				compatible = "renesas,rz-gpio"; /* in zephyr/dts/arm/renesas/rz/rzn/r9a07g084.dtsi:437 */
				gpio-controller;                /* in zephyr/dts/arm/renesas/rz/rzn/r9a07g084.dtsi:438 */
				#gpio-cells = < 0x2 >;          /* in zephyr/dts/arm/renesas/rz/rzn/r9a07g084.dtsi:439 */
				ngpios = < 0x8 >;               /* in zephyr/dts/arm/renesas/rz/rzn/r9a07g084.dtsi:440 */
				reg = < 0x500 >;                /* in zephyr/dts/arm/renesas/rz/rzn/r9a07g084.dtsi:441 */
				status = "okay";                /* in zephyr/boards/renesas/rzn2l_rsk/rzn2l_rsk.dts:111 */
				phandle = < 0xd >;              /* in zephyr/boards/renesas/rzn2l_rsk/rzn2l_rsk.dts:65 */
			};

			/* node '/soc/pinctrl@800a0000/gpio@600' defined in zephyr/dts/arm/renesas/rz/rzn/r9a07g084.dtsi:445 */
			gpio6: gpio@600 {
				compatible = "renesas,rz-gpio"; /* in zephyr/dts/arm/renesas/rz/rzn/r9a07g084.dtsi:446 */
				gpio-controller;                /* in zephyr/dts/arm/renesas/rz/rzn/r9a07g084.dtsi:447 */
				#gpio-cells = < 0x2 >;          /* in zephyr/dts/arm/renesas/rz/rzn/r9a07g084.dtsi:448 */
				ngpios = < 0x8 >;               /* in zephyr/dts/arm/renesas/rz/rzn/r9a07g084.dtsi:449 */
				reg = < 0x600 >;                /* in zephyr/dts/arm/renesas/rz/rzn/r9a07g084.dtsi:450 */
				status = "disabled";            /* in zephyr/dts/arm/renesas/rz/rzn/r9a07g084.dtsi:451 */
			};

			/* node '/soc/pinctrl@800a0000/gpio@700' defined in zephyr/dts/arm/renesas/rz/rzn/r9a07g084.dtsi:454 */
			gpio7: gpio@700 {
				compatible = "renesas,rz-gpio"; /* in zephyr/dts/arm/renesas/rz/rzn/r9a07g084.dtsi:455 */
				gpio-controller;                /* in zephyr/dts/arm/renesas/rz/rzn/r9a07g084.dtsi:456 */
				#gpio-cells = < 0x2 >;          /* in zephyr/dts/arm/renesas/rz/rzn/r9a07g084.dtsi:457 */
				ngpios = < 0x5 >;               /* in zephyr/dts/arm/renesas/rz/rzn/r9a07g084.dtsi:458 */
				reg = < 0x700 >;                /* in zephyr/dts/arm/renesas/rz/rzn/r9a07g084.dtsi:459 */
				status = "disabled";            /* in zephyr/dts/arm/renesas/rz/rzn/r9a07g084.dtsi:460 */
			};

			/* node '/soc/pinctrl@800a0000/gpio@800' defined in zephyr/dts/arm/renesas/rz/rzn/r9a07g084.dtsi:463 */
			gpio8: gpio@800 {
				compatible = "renesas,rz-gpio";     /* in zephyr/dts/arm/renesas/rz/rzn/r9a07g084.dtsi:464 */
				gpio-controller;                    /* in zephyr/dts/arm/renesas/rz/rzn/r9a07g084.dtsi:465 */
				#gpio-cells = < 0x2 >;              /* in zephyr/dts/arm/renesas/rz/rzn/r9a07g084.dtsi:466 */
				ngpios = < 0x8 >;                   /* in zephyr/dts/arm/renesas/rz/rzn/r9a07g084.dtsi:467 */
				gpio-reserved-ranges = < 0x0 0x4 >; /* in zephyr/dts/arm/renesas/rz/rzn/r9a07g084.dtsi:468 */
				reg = < 0x800 >;                    /* in zephyr/dts/arm/renesas/rz/rzn/r9a07g084.dtsi:469 */
				status = "disabled";                /* in zephyr/dts/arm/renesas/rz/rzn/r9a07g084.dtsi:470 */
			};

			/* node '/soc/pinctrl@800a0000/gpio@900' defined in zephyr/dts/arm/renesas/rz/rzn/r9a07g084.dtsi:473 */
			gpio9: gpio@900 {
				compatible = "renesas,rz-gpio"; /* in zephyr/dts/arm/renesas/rz/rzn/r9a07g084.dtsi:474 */
				gpio-controller;                /* in zephyr/dts/arm/renesas/rz/rzn/r9a07g084.dtsi:475 */
				#gpio-cells = < 0x2 >;          /* in zephyr/dts/arm/renesas/rz/rzn/r9a07g084.dtsi:476 */
				ngpios = < 0x8 >;               /* in zephyr/dts/arm/renesas/rz/rzn/r9a07g084.dtsi:477 */
				reg = < 0x900 >;                /* in zephyr/dts/arm/renesas/rz/rzn/r9a07g084.dtsi:478 */
				status = "disabled";            /* in zephyr/dts/arm/renesas/rz/rzn/r9a07g084.dtsi:479 */
			};

			/* node '/soc/pinctrl@800a0000/gpio@a00' defined in zephyr/dts/arm/renesas/rz/rzn/r9a07g084.dtsi:482 */
			gpio10: gpio@a00 {
				compatible = "renesas,rz-gpio"; /* in zephyr/dts/arm/renesas/rz/rzn/r9a07g084.dtsi:483 */
				gpio-controller;                /* in zephyr/dts/arm/renesas/rz/rzn/r9a07g084.dtsi:484 */
				#gpio-cells = < 0x2 >;          /* in zephyr/dts/arm/renesas/rz/rzn/r9a07g084.dtsi:485 */
				ngpios = < 0x5 >;               /* in zephyr/dts/arm/renesas/rz/rzn/r9a07g084.dtsi:486 */
				reg = < 0xa00 >;                /* in zephyr/dts/arm/renesas/rz/rzn/r9a07g084.dtsi:487 */
				status = "disabled";            /* in zephyr/dts/arm/renesas/rz/rzn/r9a07g084.dtsi:488 */
			};

			/* node '/soc/pinctrl@800a0000/gpio@b00' defined in zephyr/dts/arm/renesas/rz/rzn/r9a07g084.dtsi:491 */
			gpio11: gpio@b00 {
				compatible = "renesas,rz-gpio"; /* in zephyr/dts/arm/renesas/rz/rzn/r9a07g084.dtsi:492 */
				gpio-controller;                /* in zephyr/dts/arm/renesas/rz/rzn/r9a07g084.dtsi:493 */
				#gpio-cells = < 0x2 >;          /* in zephyr/dts/arm/renesas/rz/rzn/r9a07g084.dtsi:494 */
				ngpios = < 0x0 >;               /* in zephyr/dts/arm/renesas/rz/rzn/r9a07g084.dtsi:495 */
				reg = < 0xb00 >;                /* in zephyr/dts/arm/renesas/rz/rzn/r9a07g084.dtsi:496 */
				status = "disabled";            /* in zephyr/dts/arm/renesas/rz/rzn/r9a07g084.dtsi:497 */
			};

			/* node '/soc/pinctrl@800a0000/gpio@c00' defined in zephyr/dts/arm/renesas/rz/rzn/r9a07g084.dtsi:500 */
			gpio12: gpio@c00 {
				compatible = "renesas,rz-gpio";     /* in zephyr/dts/arm/renesas/rz/rzn/r9a07g084.dtsi:501 */
				gpio-controller;                    /* in zephyr/dts/arm/renesas/rz/rzn/r9a07g084.dtsi:502 */
				#gpio-cells = < 0x2 >;              /* in zephyr/dts/arm/renesas/rz/rzn/r9a07g084.dtsi:503 */
				ngpios = < 0x5 >;                   /* in zephyr/dts/arm/renesas/rz/rzn/r9a07g084.dtsi:504 */
				gpio-reserved-ranges = < 0x0 0x4 >; /* in zephyr/dts/arm/renesas/rz/rzn/r9a07g084.dtsi:505 */
				reg = < 0xc00 >;                    /* in zephyr/dts/arm/renesas/rz/rzn/r9a07g084.dtsi:506 */
				status = "disabled";                /* in zephyr/dts/arm/renesas/rz/rzn/r9a07g084.dtsi:507 */
			};

			/* node '/soc/pinctrl@800a0000/gpio@d00' defined in zephyr/dts/arm/renesas/rz/rzn/r9a07g084.dtsi:510 */
			gpio13: gpio@d00 {
				compatible = "renesas,rz-gpio";     /* in zephyr/dts/arm/renesas/rz/rzn/r9a07g084.dtsi:511 */
				gpio-controller;                    /* in zephyr/dts/arm/renesas/rz/rzn/r9a07g084.dtsi:512 */
				#gpio-cells = < 0x2 >;              /* in zephyr/dts/arm/renesas/rz/rzn/r9a07g084.dtsi:513 */
				ngpios = < 0x8 >;                   /* in zephyr/dts/arm/renesas/rz/rzn/r9a07g084.dtsi:514 */
				gpio-reserved-ranges = < 0x0 0x2 >; /* in zephyr/dts/arm/renesas/rz/rzn/r9a07g084.dtsi:515 */
				reg = < 0xd00 >;                    /* in zephyr/dts/arm/renesas/rz/rzn/r9a07g084.dtsi:516 */
				status = "disabled";                /* in zephyr/dts/arm/renesas/rz/rzn/r9a07g084.dtsi:517 */
			};

			/* node '/soc/pinctrl@800a0000/gpio@e00' defined in zephyr/dts/arm/renesas/rz/rzn/r9a07g084.dtsi:520 */
			gpio14: gpio@e00 {
				compatible = "renesas,rz-gpio"; /* in zephyr/dts/arm/renesas/rz/rzn/r9a07g084.dtsi:521 */
				gpio-controller;                /* in zephyr/dts/arm/renesas/rz/rzn/r9a07g084.dtsi:522 */
				#gpio-cells = < 0x2 >;          /* in zephyr/dts/arm/renesas/rz/rzn/r9a07g084.dtsi:523 */
				ngpios = < 0x8 >;               /* in zephyr/dts/arm/renesas/rz/rzn/r9a07g084.dtsi:524 */
				reg = < 0xe00 >;                /* in zephyr/dts/arm/renesas/rz/rzn/r9a07g084.dtsi:525 */
				status = "disabled";            /* in zephyr/dts/arm/renesas/rz/rzn/r9a07g084.dtsi:526 */
			};

			/* node '/soc/pinctrl@800a0000/gpio@f00' defined in zephyr/dts/arm/renesas/rz/rzn/r9a07g084.dtsi:529 */
			gpio15: gpio@f00 {
				compatible = "renesas,rz-gpio"; /* in zephyr/dts/arm/renesas/rz/rzn/r9a07g084.dtsi:530 */
				gpio-controller;                /* in zephyr/dts/arm/renesas/rz/rzn/r9a07g084.dtsi:531 */
				#gpio-cells = < 0x2 >;          /* in zephyr/dts/arm/renesas/rz/rzn/r9a07g084.dtsi:532 */
				ngpios = < 0x8 >;               /* in zephyr/dts/arm/renesas/rz/rzn/r9a07g084.dtsi:533 */
				reg = < 0xf00 >;                /* in zephyr/dts/arm/renesas/rz/rzn/r9a07g084.dtsi:534 */
				status = "disabled";            /* in zephyr/dts/arm/renesas/rz/rzn/r9a07g084.dtsi:535 */
			};

			/* node '/soc/pinctrl@800a0000/gpio@1000' defined in zephyr/dts/arm/renesas/rz/rzn/r9a07g084.dtsi:538 */
			gpio16: gpio@1000 {
				compatible = "renesas,rz-gpio";     /* in zephyr/dts/arm/renesas/rz/rzn/r9a07g084.dtsi:539 */
				gpio-controller;                    /* in zephyr/dts/arm/renesas/rz/rzn/r9a07g084.dtsi:540 */
				#gpio-cells = < 0x2 >;              /* in zephyr/dts/arm/renesas/rz/rzn/r9a07g084.dtsi:541 */
				ngpios = < 0x8 >;                   /* in zephyr/dts/arm/renesas/rz/rzn/r9a07g084.dtsi:542 */
				gpio-reserved-ranges = < 0x4 0x1 >; /* in zephyr/dts/arm/renesas/rz/rzn/r9a07g084.dtsi:543 */
				reg = < 0x1000 >;                   /* in zephyr/dts/arm/renesas/rz/rzn/r9a07g084.dtsi:544 */
				irqs = < 0x3 0x7 >;                 /* in zephyr/boards/renesas/rzn2l_rsk/rzn2l_rsk.dts:106 */
				status = "okay";                    /* in zephyr/boards/renesas/rzn2l_rsk/rzn2l_rsk.dts:107 */
				phandle = < 0xc >;                  /* in zephyr/boards/renesas/rzn2l_rsk/rzn2l_rsk.dts:59 */
			};

			/* node '/soc/pinctrl@800a0000/gpio@1100' defined in zephyr/dts/arm/renesas/rz/rzn/r9a07g084.dtsi:548 */
			gpio17: gpio@1100 {
				compatible = "renesas,rz-gpio";     /* in zephyr/dts/arm/renesas/rz/rzn/r9a07g084.dtsi:549 */
				gpio-controller;                    /* in zephyr/dts/arm/renesas/rz/rzn/r9a07g084.dtsi:550 */
				#gpio-cells = < 0x2 >;              /* in zephyr/dts/arm/renesas/rz/rzn/r9a07g084.dtsi:551 */
				ngpios = < 0x8 >;                   /* in zephyr/dts/arm/renesas/rz/rzn/r9a07g084.dtsi:552 */
				gpio-reserved-ranges = < 0x1 0x2 >; /* in zephyr/dts/arm/renesas/rz/rzn/r9a07g084.dtsi:553 */
				reg = < 0x1100 >;                   /* in zephyr/dts/arm/renesas/rz/rzn/r9a07g084.dtsi:554 */
				status = "okay";                    /* in zephyr/boards/renesas/rzn2l_rsk/rzn2l_rsk.dts:95 */
				phandle = < 0xb >;                  /* in zephyr/boards/renesas/rzn2l_rsk/rzn2l_rsk.dts:49 */
			};

			/* node '/soc/pinctrl@800a0000/gpio@1200' defined in zephyr/dts/arm/renesas/rz/rzn/r9a07g084.dtsi:558 */
			gpio18: gpio@1200 {
				compatible = "renesas,rz-gpio"; /* in zephyr/dts/arm/renesas/rz/rzn/r9a07g084.dtsi:559 */
				gpio-controller;                /* in zephyr/dts/arm/renesas/rz/rzn/r9a07g084.dtsi:560 */
				#gpio-cells = < 0x2 >;          /* in zephyr/dts/arm/renesas/rz/rzn/r9a07g084.dtsi:561 */
				ngpios = < 0x7 >;               /* in zephyr/dts/arm/renesas/rz/rzn/r9a07g084.dtsi:562 */
				reg = < 0x1200 >;               /* in zephyr/dts/arm/renesas/rz/rzn/r9a07g084.dtsi:563 */
				status = "okay";                /* in zephyr/boards/renesas/rzn2l_rsk/rzn2l_rsk.dts:83 */
				phandle = < 0x8 >;              /* in zephyr/boards/renesas/rzn2l_rsk/rzn2l_rsk.dts:34 */
			};

			/* node '/soc/pinctrl@800a0000/gpio@1300' defined in zephyr/dts/arm/renesas/rz/rzn/r9a07g084.dtsi:567 */
			gpio19: gpio@1300 {
				compatible = "renesas,rz-gpio"; /* in zephyr/dts/arm/renesas/rz/rzn/r9a07g084.dtsi:568 */
				gpio-controller;                /* in zephyr/dts/arm/renesas/rz/rzn/r9a07g084.dtsi:569 */
				#gpio-cells = < 0x2 >;          /* in zephyr/dts/arm/renesas/rz/rzn/r9a07g084.dtsi:570 */
				ngpios = < 0x1 >;               /* in zephyr/dts/arm/renesas/rz/rzn/r9a07g084.dtsi:571 */
				reg = < 0x1300 >;               /* in zephyr/dts/arm/renesas/rz/rzn/r9a07g084.dtsi:572 */
				status = "disabled";            /* in zephyr/dts/arm/renesas/rz/rzn/r9a07g084.dtsi:573 */
			};

			/* node '/soc/pinctrl@800a0000/gpio@1400' defined in zephyr/dts/arm/renesas/rz/rzn/r9a07g084.dtsi:576 */
			gpio20: gpio@1400 {
				compatible = "renesas,rz-gpio";     /* in zephyr/dts/arm/renesas/rz/rzn/r9a07g084.dtsi:577 */
				gpio-controller;                    /* in zephyr/dts/arm/renesas/rz/rzn/r9a07g084.dtsi:578 */
				#gpio-cells = < 0x2 >;              /* in zephyr/dts/arm/renesas/rz/rzn/r9a07g084.dtsi:579 */
				ngpios = < 0x5 >;                   /* in zephyr/dts/arm/renesas/rz/rzn/r9a07g084.dtsi:580 */
				gpio-reserved-ranges = < 0x0 0x1 >; /* in zephyr/dts/arm/renesas/rz/rzn/r9a07g084.dtsi:581 */
				reg = < 0x1400 >;                   /* in zephyr/dts/arm/renesas/rz/rzn/r9a07g084.dtsi:582 */
				status = "disabled";                /* in zephyr/dts/arm/renesas/rz/rzn/r9a07g084.dtsi:583 */
			};

			/* node '/soc/pinctrl@800a0000/gpio@1500' defined in zephyr/dts/arm/renesas/rz/rzn/r9a07g084.dtsi:586 */
			gpio21: gpio@1500 {
				compatible = "renesas,rz-gpio";     /* in zephyr/dts/arm/renesas/rz/rzn/r9a07g084.dtsi:587 */
				gpio-controller;                    /* in zephyr/dts/arm/renesas/rz/rzn/r9a07g084.dtsi:588 */
				#gpio-cells = < 0x2 >;              /* in zephyr/dts/arm/renesas/rz/rzn/r9a07g084.dtsi:589 */
				ngpios = < 0x8 >;                   /* in zephyr/dts/arm/renesas/rz/rzn/r9a07g084.dtsi:590 */
				gpio-reserved-ranges = < 0x0 0x1 >; /* in zephyr/dts/arm/renesas/rz/rzn/r9a07g084.dtsi:591 */
				reg = < 0x1500 >;                   /* in zephyr/dts/arm/renesas/rz/rzn/r9a07g084.dtsi:592 */
				status = "disabled";                /* in zephyr/dts/arm/renesas/rz/rzn/r9a07g084.dtsi:593 */
			};

			/* node '/soc/pinctrl@800a0000/gpio@1600' defined in zephyr/dts/arm/renesas/rz/rzn/r9a07g084.dtsi:596 */
			gpio22: gpio@1600 {
				compatible = "renesas,rz-gpio"; /* in zephyr/dts/arm/renesas/rz/rzn/r9a07g084.dtsi:597 */
				gpio-controller;                /* in zephyr/dts/arm/renesas/rz/rzn/r9a07g084.dtsi:598 */
				#gpio-cells = < 0x2 >;          /* in zephyr/dts/arm/renesas/rz/rzn/r9a07g084.dtsi:599 */
				ngpios = < 0x4 >;               /* in zephyr/dts/arm/renesas/rz/rzn/r9a07g084.dtsi:600 */
				reg = < 0x1600 >;               /* in zephyr/dts/arm/renesas/rz/rzn/r9a07g084.dtsi:601 */
				status = "okay";                /* in zephyr/boards/renesas/rzn2l_rsk/rzn2l_rsk.dts:87 */
				phandle = < 0x9 >;              /* in zephyr/boards/renesas/rzn2l_rsk/rzn2l_rsk.dts:39 */
			};

			/* node '/soc/pinctrl@800a0000/gpio@1700' defined in zephyr/dts/arm/renesas/rz/rzn/r9a07g084.dtsi:605 */
			gpio23: gpio@1700 {
				compatible = "renesas,rz-gpio";     /* in zephyr/dts/arm/renesas/rz/rzn/r9a07g084.dtsi:606 */
				gpio-controller;                    /* in zephyr/dts/arm/renesas/rz/rzn/r9a07g084.dtsi:607 */
				#gpio-cells = < 0x2 >;              /* in zephyr/dts/arm/renesas/rz/rzn/r9a07g084.dtsi:608 */
				ngpios = < 0x8 >;                   /* in zephyr/dts/arm/renesas/rz/rzn/r9a07g084.dtsi:609 */
				gpio-reserved-ranges = < 0x0 0x7 >; /* in zephyr/dts/arm/renesas/rz/rzn/r9a07g084.dtsi:610 */
				reg = < 0x1700 >;                   /* in zephyr/dts/arm/renesas/rz/rzn/r9a07g084.dtsi:611 */
				status = "disabled";                /* in zephyr/dts/arm/renesas/rz/rzn/r9a07g084.dtsi:612 */
			};

			/* node '/soc/pinctrl@800a0000/gpio@1800' defined in zephyr/dts/arm/renesas/rz/rzn/r9a07g084.dtsi:615 */
			gpio24: gpio@1800 {
				compatible = "renesas,rz-gpio"; /* in zephyr/dts/arm/renesas/rz/rzn/r9a07g084.dtsi:616 */
				gpio-controller;                /* in zephyr/dts/arm/renesas/rz/rzn/r9a07g084.dtsi:617 */
				#gpio-cells = < 0x2 >;          /* in zephyr/dts/arm/renesas/rz/rzn/r9a07g084.dtsi:618 */
				ngpios = < 0x3 >;               /* in zephyr/dts/arm/renesas/rz/rzn/r9a07g084.dtsi:619 */
				reg = < 0x1800 >;               /* in zephyr/dts/arm/renesas/rz/rzn/r9a07g084.dtsi:620 */
				status = "disabled";            /* in zephyr/dts/arm/renesas/rz/rzn/r9a07g084.dtsi:621 */
			};

			/* node '/soc/pinctrl@800a0000/sci0_default' defined in zephyr/boards/renesas/rzn2l_rsk/rzn2l_rsk-pinctrl.dtsi:10 */
			sci0_default: sci0_default {
				phandle = < 0x4 >; /* in zephyr/boards/renesas/rzn2l_rsk/rzn2l_rsk.dts:72 */

				/* node '/soc/pinctrl@800a0000/sci0_default/sci0-pinmux' defined in zephyr/boards/renesas/rzn2l_rsk/rzn2l_rsk-pinctrl.dtsi:11 */
				sci0-pinmux {
					pinmux = < 0x1015 >,
					         < 0x1026 >; /* in zephyr/boards/renesas/rzn2l_rsk/rzn2l_rsk-pinctrl.dtsi:12 */
				};
			};

			/* node '/soc/pinctrl@800a0000/irq7_default' defined in zephyr/boards/renesas/rzn2l_rsk/rzn2l_rsk-pinctrl.dtsi:24 */
			irq7_default: irq7_default {
				phandle = < 0x3 >; /* in zephyr/boards/renesas/rzn2l_rsk/rzn2l_rsk.dts:100 */

				/* node '/soc/pinctrl@800a0000/irq7_default/irq7-pinmux' defined in zephyr/boards/renesas/rzn2l_rsk/rzn2l_rsk-pinctrl.dtsi:25 */
				irq7-pinmux {
					pinmux = < 0x1003 >; /* in zephyr/boards/renesas/rzn2l_rsk/rzn2l_rsk-pinctrl.dtsi:26 */
					input-enable;        /* in zephyr/boards/renesas/rzn2l_rsk/rzn2l_rsk-pinctrl.dtsi:27 */
				};
			};

			/* node '/soc/pinctrl@800a0000/i2c1_default' defined in zephyr/boards/renesas/rzn2l_rsk/rzn2l_rsk-pinctrl.dtsi:45 */
			i2c1_default: i2c1_default {
				phandle = < 0x5 >; /* in zephyr/boards/renesas/rzn2l_rsk/rzn2l_rsk.dts:123 */

				/* node '/soc/pinctrl@800a0000/i2c1_default/i2c1-pinmux' defined in zephyr/boards/renesas/rzn2l_rsk/rzn2l_rsk-pinctrl.dtsi:46 */
				i2c1-pinmux {
					pinmux = < 0x582 >,
					         < 0x593 >; /* in zephyr/boards/renesas/rzn2l_rsk/rzn2l_rsk-pinctrl.dtsi:47 */
				};
			};

			/* node '/soc/pinctrl@800a0000/spi2' defined in zephyr/boards/renesas/rzn2l_rsk/rzn2l_rsk-pinctrl.dtsi:52 */
			spi2_pins: spi2 {
				phandle = < 0x6 >; /* in zephyr/boards/renesas/rzn2l_rsk/rzn2l_rsk.dts:129 */

				/* node '/soc/pinctrl@800a0000/spi2/spi2-pinmux' defined in zephyr/boards/renesas/rzn2l_rsk/rzn2l_rsk-pinctrl.dtsi:53 */
				spi2-pinmux {
					pinmux = < 0x1234 >,
					         < 0x1235 >,
					         < 0x1256 >,
					         < 0x1561 >; /* in zephyr/boards/renesas/rzn2l_rsk/rzn2l_rsk-pinctrl.dtsi:54 */
				};
			};

			/* node '/soc/pinctrl@800a0000/xspi0_default' defined in zephyr/boards/renesas/rzn2l_rsk/rzn2l_rsk-pinctrl.dtsi:61 */
			xspi0_default: xspi0_default {
				phandle = < 0x7 >; /* in zephyr/boards/renesas/rzn2l_rsk/rzn2l_rsk.dts:139 */

				/* node '/soc/pinctrl@800a0000/xspi0_default/xspi0-pinmux' defined in zephyr/boards/renesas/rzn2l_rsk/rzn2l_rsk-pinctrl.dtsi:62 */
				xspi0-pinmux {
					pinmux = < 0xe06 >,
					         < 0xe05 >,
					         < 0xf07 >,
					         < 0xe07 >,
					         < 0xf00 >,
					         < 0xf01 >,
					         < 0xf02 >,
					         < 0x1001 >,
					         < 0x1013 >; /* in zephyr/boards/renesas/rzn2l_rsk/rzn2l_rsk-pinctrl.dtsi:63 */
				};
			};
		};

		/* node '/soc/sci0@80001000' defined in zephyr/dts/arm/renesas/rz/rzn/r9a07g084.dtsi:625 */
		sci0: sci0@80001000 {
			compatible = "renesas,rz-sci";       /* in zephyr/dts/arm/renesas/rz/rzn/r9a07g084.dtsi:626 */
			reg = < 0x80001000 0x400 >;          /* in zephyr/dts/arm/renesas/rz/rzn/r9a07g084.dtsi:627 */
			channel = < 0x0 >;                   /* in zephyr/dts/arm/renesas/rz/rzn/r9a07g084.dtsi:628 */
			interrupts = < 0x0 0x120 0x2 0xa0 >,
			             < 0x0 0x121 0x4 0xa0 >,
			             < 0x0 0x122 0x4 0xa0 >,
			             < 0x0 0x123 0x2 0xa0 >; /* in zephyr/dts/arm/renesas/rz/rzn/r9a07g084.dtsi:629 */
			interrupt-names = "eri",
			                  "rxi",
			                  "txi",
			                  "tei";             /* in zephyr/dts/arm/renesas/rz/rzn/r9a07g084.dtsi:633 */
			pinctrl-0 = < &sci0_default >;       /* in zephyr/boards/renesas/rzn2l_rsk/rzn2l_rsk.dts:72 */
			pinctrl-names = "default";           /* in zephyr/boards/renesas/rzn2l_rsk/rzn2l_rsk.dts:73 */
			status = "okay";                     /* in zephyr/boards/renesas/rzn2l_rsk/rzn2l_rsk.dts:74 */

			/* node '/soc/sci0@80001000/uart' defined in zephyr/dts/arm/renesas/rz/rzn/r9a07g084.dtsi:636 */
			uart0: uart {
				compatible = "renesas,rz-sci-uart"; /* in zephyr/dts/arm/renesas/rz/rzn/r9a07g084.dtsi:637 */
				current-speed = < 0x1c200 >;        /* in zephyr/boards/renesas/rzn2l_rsk/rzn2l_rsk.dts:77 */
				status = "okay";                    /* in zephyr/boards/renesas/rzn2l_rsk/rzn2l_rsk.dts:78 */
			};
		};

		/* node '/soc/sci1@80001400' defined in zephyr/dts/arm/renesas/rz/rzn/r9a07g084.dtsi:643 */
		sci1: sci1@80001400 {
			compatible = "renesas,rz-sci";       /* in zephyr/dts/arm/renesas/rz/rzn/r9a07g084.dtsi:644 */
			reg = < 0x80001400 0x400 >;          /* in zephyr/dts/arm/renesas/rz/rzn/r9a07g084.dtsi:645 */
			channel = < 0x1 >;                   /* in zephyr/dts/arm/renesas/rz/rzn/r9a07g084.dtsi:646 */
			interrupts = < 0x0 0x124 0x2 0xa0 >,
			             < 0x0 0x125 0x4 0xa0 >,
			             < 0x0 0x126 0x4 0xa0 >,
			             < 0x0 0x127 0x2 0xa0 >; /* in zephyr/dts/arm/renesas/rz/rzn/r9a07g084.dtsi:647 */
			interrupt-names = "eri",
			                  "rxi",
			                  "txi",
			                  "tei";             /* in zephyr/dts/arm/renesas/rz/rzn/r9a07g084.dtsi:651 */
			status = "disabled";                 /* in zephyr/dts/arm/renesas/rz/rzn/r9a07g084.dtsi:652 */

			/* node '/soc/sci1@80001400/uart' defined in zephyr/dts/arm/renesas/rz/rzn/r9a07g084.dtsi:654 */
			uart {
				compatible = "renesas,rz-sci-uart"; /* in zephyr/dts/arm/renesas/rz/rzn/r9a07g084.dtsi:655 */
				current-speed = < 0x1c200 >;        /* in zephyr/dts/arm/renesas/rz/rzn/r9a07g084.dtsi:656 */
				status = "disabled";                /* in zephyr/dts/arm/renesas/rz/rzn/r9a07g084.dtsi:657 */
			};
		};

		/* node '/soc/sci2@80001800' defined in zephyr/dts/arm/renesas/rz/rzn/r9a07g084.dtsi:661 */
		sci2: sci2@80001800 {
			compatible = "renesas,rz-sci";       /* in zephyr/dts/arm/renesas/rz/rzn/r9a07g084.dtsi:662 */
			reg = < 0x80001800 0x400 >;          /* in zephyr/dts/arm/renesas/rz/rzn/r9a07g084.dtsi:663 */
			channel = < 0x2 >;                   /* in zephyr/dts/arm/renesas/rz/rzn/r9a07g084.dtsi:664 */
			interrupts = < 0x0 0x128 0x2 0xa0 >,
			             < 0x0 0x129 0x4 0xa0 >,
			             < 0x0 0x12a 0x4 0xa0 >,
			             < 0x0 0x12b 0x2 0xa0 >; /* in zephyr/dts/arm/renesas/rz/rzn/r9a07g084.dtsi:665 */
			interrupt-names = "eri",
			                  "rxi",
			                  "txi",
			                  "tei";             /* in zephyr/dts/arm/renesas/rz/rzn/r9a07g084.dtsi:669 */
			status = "disabled";                 /* in zephyr/dts/arm/renesas/rz/rzn/r9a07g084.dtsi:670 */

			/* node '/soc/sci2@80001800/uart' defined in zephyr/dts/arm/renesas/rz/rzn/r9a07g084.dtsi:672 */
			uart {
				compatible = "renesas,rz-sci-uart"; /* in zephyr/dts/arm/renesas/rz/rzn/r9a07g084.dtsi:673 */
				current-speed = < 0x1c200 >;        /* in zephyr/dts/arm/renesas/rz/rzn/r9a07g084.dtsi:674 */
				status = "disabled";                /* in zephyr/dts/arm/renesas/rz/rzn/r9a07g084.dtsi:675 */
			};
		};

		/* node '/soc/sci3@80001c00' defined in zephyr/dts/arm/renesas/rz/rzn/r9a07g084.dtsi:679 */
		sci3: sci3@80001c00 {
			compatible = "renesas,rz-sci";       /* in zephyr/dts/arm/renesas/rz/rzn/r9a07g084.dtsi:680 */
			reg = < 0x80001c00 0x400 >;          /* in zephyr/dts/arm/renesas/rz/rzn/r9a07g084.dtsi:681 */
			channel = < 0x3 >;                   /* in zephyr/dts/arm/renesas/rz/rzn/r9a07g084.dtsi:682 */
			interrupts = < 0x0 0x12c 0x2 0xa0 >,
			             < 0x0 0x12d 0x4 0xa0 >,
			             < 0x0 0x12e 0x4 0xa0 >,
			             < 0x0 0x12f 0x2 0xa0 >; /* in zephyr/dts/arm/renesas/rz/rzn/r9a07g084.dtsi:683 */
			interrupt-names = "eri",
			                  "rxi",
			                  "txi",
			                  "tei";             /* in zephyr/dts/arm/renesas/rz/rzn/r9a07g084.dtsi:687 */
			status = "disabled";                 /* in zephyr/dts/arm/renesas/rz/rzn/r9a07g084.dtsi:688 */

			/* node '/soc/sci3@80001c00/uart' defined in zephyr/dts/arm/renesas/rz/rzn/r9a07g084.dtsi:690 */
			uart {
				compatible = "renesas,rz-sci-uart"; /* in zephyr/dts/arm/renesas/rz/rzn/r9a07g084.dtsi:691 */
				current-speed = < 0x1c200 >;        /* in zephyr/dts/arm/renesas/rz/rzn/r9a07g084.dtsi:692 */
				status = "disabled";                /* in zephyr/dts/arm/renesas/rz/rzn/r9a07g084.dtsi:693 */
			};
		};

		/* node '/soc/sci4@80002000' defined in zephyr/dts/arm/renesas/rz/rzn/r9a07g084.dtsi:697 */
		sci4: sci4@80002000 {
			compatible = "renesas,rz-sci";       /* in zephyr/dts/arm/renesas/rz/rzn/r9a07g084.dtsi:698 */
			reg = < 0x80002000 0x400 >;          /* in zephyr/dts/arm/renesas/rz/rzn/r9a07g084.dtsi:699 */
			channel = < 0x4 >;                   /* in zephyr/dts/arm/renesas/rz/rzn/r9a07g084.dtsi:700 */
			interrupts = < 0x0 0x130 0x2 0xa0 >,
			             < 0x0 0x131 0x4 0xa0 >,
			             < 0x0 0x132 0x4 0xa0 >,
			             < 0x0 0x133 0x2 0xa0 >; /* in zephyr/dts/arm/renesas/rz/rzn/r9a07g084.dtsi:701 */
			interrupt-names = "eri",
			                  "rxi",
			                  "txi",
			                  "tei";             /* in zephyr/dts/arm/renesas/rz/rzn/r9a07g084.dtsi:705 */
			status = "disabled";                 /* in zephyr/dts/arm/renesas/rz/rzn/r9a07g084.dtsi:706 */

			/* node '/soc/sci4@80002000/uart' defined in zephyr/dts/arm/renesas/rz/rzn/r9a07g084.dtsi:708 */
			uart {
				compatible = "renesas,rz-sci-uart"; /* in zephyr/dts/arm/renesas/rz/rzn/r9a07g084.dtsi:709 */
				current-speed = < 0x1c200 >;        /* in zephyr/dts/arm/renesas/rz/rzn/r9a07g084.dtsi:710 */
				status = "disabled";                /* in zephyr/dts/arm/renesas/rz/rzn/r9a07g084.dtsi:711 */
			};
		};

		/* node '/soc/sci5@81001000' defined in zephyr/dts/arm/renesas/rz/rzn/r9a07g084.dtsi:715 */
		sci5: sci5@81001000 {
			compatible = "renesas,rz-sci";       /* in zephyr/dts/arm/renesas/rz/rzn/r9a07g084.dtsi:716 */
			reg = < 0x81001000 0x400 >;          /* in zephyr/dts/arm/renesas/rz/rzn/r9a07g084.dtsi:717 */
			channel = < 0x5 >;                   /* in zephyr/dts/arm/renesas/rz/rzn/r9a07g084.dtsi:718 */
			interrupts = < 0x0 0x1b3 0x2 0xa0 >,
			             < 0x0 0x1b4 0x4 0xa0 >,
			             < 0x0 0x1b5 0x4 0xa0 >,
			             < 0x0 0x1b6 0x2 0xa0 >; /* in zephyr/dts/arm/renesas/rz/rzn/r9a07g084.dtsi:719 */
			interrupt-names = "eri",
			                  "rxi",
			                  "txi",
			                  "tei";             /* in zephyr/dts/arm/renesas/rz/rzn/r9a07g084.dtsi:723 */
			status = "disabled";                 /* in zephyr/dts/arm/renesas/rz/rzn/r9a07g084.dtsi:724 */

			/* node '/soc/sci5@81001000/uart' defined in zephyr/dts/arm/renesas/rz/rzn/r9a07g084.dtsi:726 */
			uart {
				compatible = "renesas,rz-sci-uart"; /* in zephyr/dts/arm/renesas/rz/rzn/r9a07g084.dtsi:727 */
				current-speed = < 0x1c200 >;        /* in zephyr/dts/arm/renesas/rz/rzn/r9a07g084.dtsi:728 */
				status = "disabled";                /* in zephyr/dts/arm/renesas/rz/rzn/r9a07g084.dtsi:729 */
			};
		};

		/* node '/soc/gpt0@90002000' defined in zephyr/dts/arm/renesas/rz/rzn/r9a07g084.dtsi:733 */
		gpt0: gpt0@90002000 {
			compatible = "renesas,rz-gpt";      /* in zephyr/dts/arm/renesas/rz/rzn/r9a07g084.dtsi:734 */
			reg = < 0x90002000 0x100 >;         /* in zephyr/dts/arm/renesas/rz/rzn/r9a07g084.dtsi:735 */
			channel = < 0x0 >;                  /* in zephyr/dts/arm/renesas/rz/rzn/r9a07g084.dtsi:736 */
			interrupts = < 0x0 0x74 0x4 0xa0 >,
			             < 0x0 0x75 0x4 0xa0 >,
			             < 0x0 0x76 0x4 0xa0 >,
			             < 0x0 0x77 0x4 0xa0 >,
			             < 0x0 0x78 0x4 0xa0 >,
			             < 0x0 0x79 0x4 0xa0 >,
			             < 0x0 0x7a 0x4 0xa0 >,
			             < 0x0 0x7b 0x4 0xa0 >,
			             < 0x0 0x7c 0x4 0xa0 >; /* in zephyr/dts/arm/renesas/rz/rzn/r9a07g084.dtsi:737 */
			interrupt-names = "ccmpa",
			                  "ccmpb",
			                  "cmpc",
			                  "cmpd",
			                  "cmpe",
			                  "cmpf",
			                  "ovf",
			                  "udf",
			                  "dte";            /* in zephyr/dts/arm/renesas/rz/rzn/r9a07g084.dtsi:746 */
			prescaler = < 0x1 >;                /* in zephyr/dts/arm/renesas/rz/rzn/r9a07g084.dtsi:748 */
			status = "disabled";                /* in zephyr/dts/arm/renesas/rz/rzn/r9a07g084.dtsi:749 */

			/* node '/soc/gpt0@90002000/pwm' defined in zephyr/dts/arm/renesas/rz/rzn/r9a07g084.dtsi:751 */
			pwm {
				compatible = "renesas,rz-gpt-pwm"; /* in zephyr/dts/arm/renesas/rz/rzn/r9a07g084.dtsi:752 */
				#pwm-cells = < 0x3 >;              /* in zephyr/dts/arm/renesas/rz/rzn/r9a07g084.dtsi:753 */
				status = "disabled";               /* in zephyr/dts/arm/renesas/rz/rzn/r9a07g084.dtsi:754 */
			};
		};

		/* node '/soc/gpt1@90002100' defined in zephyr/dts/arm/renesas/rz/rzn/r9a07g084.dtsi:758 */
		gpt1: gpt1@90002100 {
			compatible = "renesas,rz-gpt";      /* in zephyr/dts/arm/renesas/rz/rzn/r9a07g084.dtsi:759 */
			reg = < 0x90002100 0x100 >;         /* in zephyr/dts/arm/renesas/rz/rzn/r9a07g084.dtsi:760 */
			channel = < 0x1 >;                  /* in zephyr/dts/arm/renesas/rz/rzn/r9a07g084.dtsi:761 */
			interrupts = < 0x0 0x7d 0x4 0xa0 >,
			             < 0x0 0x7e 0x4 0xa0 >,
			             < 0x0 0x7f 0x4 0xa0 >,
			             < 0x0 0x80 0x4 0xa0 >,
			             < 0x0 0x81 0x4 0xa0 >,
			             < 0x0 0x82 0x4 0xa0 >,
			             < 0x0 0x83 0x4 0xa0 >,
			             < 0x0 0x84 0x4 0xa0 >,
			             < 0x0 0x85 0x4 0xa0 >; /* in zephyr/dts/arm/renesas/rz/rzn/r9a07g084.dtsi:762 */
			interrupt-names = "ccmpa",
			                  "ccmpb",
			                  "cmpc",
			                  "cmpd",
			                  "cmpe",
			                  "cmpf",
			                  "ovf",
			                  "udf",
			                  "dte";            /* in zephyr/dts/arm/renesas/rz/rzn/r9a07g084.dtsi:771 */
			prescaler = < 0x1 >;                /* in zephyr/dts/arm/renesas/rz/rzn/r9a07g084.dtsi:773 */
			status = "disabled";                /* in zephyr/dts/arm/renesas/rz/rzn/r9a07g084.dtsi:774 */

			/* node '/soc/gpt1@90002100/pwm' defined in zephyr/dts/arm/renesas/rz/rzn/r9a07g084.dtsi:776 */
			pwm {
				compatible = "renesas,rz-gpt-pwm"; /* in zephyr/dts/arm/renesas/rz/rzn/r9a07g084.dtsi:777 */
				#pwm-cells = < 0x3 >;              /* in zephyr/dts/arm/renesas/rz/rzn/r9a07g084.dtsi:778 */
				status = "disabled";               /* in zephyr/dts/arm/renesas/rz/rzn/r9a07g084.dtsi:779 */
			};
		};

		/* node '/soc/gpt2@90002200' defined in zephyr/dts/arm/renesas/rz/rzn/r9a07g084.dtsi:783 */
		gpt2: gpt2@90002200 {
			compatible = "renesas,rz-gpt";      /* in zephyr/dts/arm/renesas/rz/rzn/r9a07g084.dtsi:784 */
			reg = < 0x90002200 0x100 >;         /* in zephyr/dts/arm/renesas/rz/rzn/r9a07g084.dtsi:785 */
			channel = < 0x2 >;                  /* in zephyr/dts/arm/renesas/rz/rzn/r9a07g084.dtsi:786 */
			interrupts = < 0x0 0x86 0x4 0xa0 >,
			             < 0x0 0x87 0x4 0xa0 >,
			             < 0x0 0x88 0x4 0xa0 >,
			             < 0x0 0x89 0x4 0xa0 >,
			             < 0x0 0x8a 0x4 0xa0 >,
			             < 0x0 0x8b 0x4 0xa0 >,
			             < 0x0 0x8c 0x4 0xa0 >,
			             < 0x0 0x8d 0x4 0xa0 >,
			             < 0x0 0x8e 0x4 0xa0 >; /* in zephyr/dts/arm/renesas/rz/rzn/r9a07g084.dtsi:787 */
			interrupt-names = "ccmpa",
			                  "ccmpb",
			                  "cmpc",
			                  "cmpd",
			                  "cmpe",
			                  "cmpf",
			                  "ovf",
			                  "udf",
			                  "dte";            /* in zephyr/dts/arm/renesas/rz/rzn/r9a07g084.dtsi:796 */
			prescaler = < 0x1 >;                /* in zephyr/dts/arm/renesas/rz/rzn/r9a07g084.dtsi:798 */
			status = "disabled";                /* in zephyr/dts/arm/renesas/rz/rzn/r9a07g084.dtsi:799 */

			/* node '/soc/gpt2@90002200/pwm' defined in zephyr/dts/arm/renesas/rz/rzn/r9a07g084.dtsi:801 */
			pwm {
				compatible = "renesas,rz-gpt-pwm"; /* in zephyr/dts/arm/renesas/rz/rzn/r9a07g084.dtsi:802 */
				#pwm-cells = < 0x3 >;              /* in zephyr/dts/arm/renesas/rz/rzn/r9a07g084.dtsi:803 */
				status = "disabled";               /* in zephyr/dts/arm/renesas/rz/rzn/r9a07g084.dtsi:804 */
			};
		};

		/* node '/soc/gpt3@90002300' defined in zephyr/dts/arm/renesas/rz/rzn/r9a07g084.dtsi:808 */
		gpt3: gpt3@90002300 {
			compatible = "renesas,rz-gpt";      /* in zephyr/dts/arm/renesas/rz/rzn/r9a07g084.dtsi:809 */
			reg = < 0x90002300 0x100 >;         /* in zephyr/dts/arm/renesas/rz/rzn/r9a07g084.dtsi:810 */
			channel = < 0x3 >;                  /* in zephyr/dts/arm/renesas/rz/rzn/r9a07g084.dtsi:811 */
			interrupts = < 0x0 0x8f 0x4 0xa0 >,
			             < 0x0 0x90 0x4 0xa0 >,
			             < 0x0 0x91 0x4 0xa0 >,
			             < 0x0 0x92 0x4 0xa0 >,
			             < 0x0 0x93 0x4 0xa0 >,
			             < 0x0 0x94 0x4 0xa0 >,
			             < 0x0 0x95 0x4 0xa0 >,
			             < 0x0 0x96 0x4 0xa0 >,
			             < 0x0 0x97 0x4 0xa0 >; /* in zephyr/dts/arm/renesas/rz/rzn/r9a07g084.dtsi:812 */
			interrupt-names = "ccmpa",
			                  "ccmpb",
			                  "cmpc",
			                  "cmpd",
			                  "cmpe",
			                  "cmpf",
			                  "ovf",
			                  "udf",
			                  "dte";            /* in zephyr/dts/arm/renesas/rz/rzn/r9a07g084.dtsi:821 */
			prescaler = < 0x1 >;                /* in zephyr/dts/arm/renesas/rz/rzn/r9a07g084.dtsi:823 */
			status = "disabled";                /* in zephyr/dts/arm/renesas/rz/rzn/r9a07g084.dtsi:824 */

			/* node '/soc/gpt3@90002300/pwm' defined in zephyr/dts/arm/renesas/rz/rzn/r9a07g084.dtsi:826 */
			pwm {
				compatible = "renesas,rz-gpt-pwm"; /* in zephyr/dts/arm/renesas/rz/rzn/r9a07g084.dtsi:827 */
				#pwm-cells = < 0x3 >;              /* in zephyr/dts/arm/renesas/rz/rzn/r9a07g084.dtsi:828 */
				status = "disabled";               /* in zephyr/dts/arm/renesas/rz/rzn/r9a07g084.dtsi:829 */
			};
		};

		/* node '/soc/gpt4@90002400' defined in zephyr/dts/arm/renesas/rz/rzn/r9a07g084.dtsi:833 */
		gpt4: gpt4@90002400 {
			compatible = "renesas,rz-gpt";      /* in zephyr/dts/arm/renesas/rz/rzn/r9a07g084.dtsi:834 */
			reg = < 0x90002400 0x100 >;         /* in zephyr/dts/arm/renesas/rz/rzn/r9a07g084.dtsi:835 */
			channel = < 0x4 >;                  /* in zephyr/dts/arm/renesas/rz/rzn/r9a07g084.dtsi:836 */
			interrupts = < 0x0 0x98 0x4 0xa0 >,
			             < 0x0 0x99 0x4 0xa0 >,
			             < 0x0 0x9a 0x4 0xa0 >,
			             < 0x0 0x9b 0x4 0xa0 >,
			             < 0x0 0x9c 0x4 0xa0 >,
			             < 0x0 0x9d 0x4 0xa0 >,
			             < 0x0 0x9e 0x4 0xa0 >,
			             < 0x0 0x9f 0x4 0xa0 >,
			             < 0x0 0xa0 0x4 0xa0 >; /* in zephyr/dts/arm/renesas/rz/rzn/r9a07g084.dtsi:837 */
			interrupt-names = "ccmpa",
			                  "ccmpb",
			                  "cmpc",
			                  "cmpd",
			                  "cmpe",
			                  "cmpf",
			                  "ovf",
			                  "udf",
			                  "dte";            /* in zephyr/dts/arm/renesas/rz/rzn/r9a07g084.dtsi:846 */
			prescaler = < 0x1 >;                /* in zephyr/dts/arm/renesas/rz/rzn/r9a07g084.dtsi:848 */
			status = "disabled";                /* in zephyr/dts/arm/renesas/rz/rzn/r9a07g084.dtsi:849 */

			/* node '/soc/gpt4@90002400/pwm' defined in zephyr/dts/arm/renesas/rz/rzn/r9a07g084.dtsi:851 */
			pwm {
				compatible = "renesas,rz-gpt-pwm"; /* in zephyr/dts/arm/renesas/rz/rzn/r9a07g084.dtsi:852 */
				#pwm-cells = < 0x3 >;              /* in zephyr/dts/arm/renesas/rz/rzn/r9a07g084.dtsi:853 */
				status = "disabled";               /* in zephyr/dts/arm/renesas/rz/rzn/r9a07g084.dtsi:854 */
			};
		};

		/* node '/soc/gpt5@90002500' defined in zephyr/dts/arm/renesas/rz/rzn/r9a07g084.dtsi:858 */
		gpt5: gpt5@90002500 {
			compatible = "renesas,rz-gpt";      /* in zephyr/dts/arm/renesas/rz/rzn/r9a07g084.dtsi:859 */
			reg = < 0x90002500 0x100 >;         /* in zephyr/dts/arm/renesas/rz/rzn/r9a07g084.dtsi:860 */
			channel = < 0x5 >;                  /* in zephyr/dts/arm/renesas/rz/rzn/r9a07g084.dtsi:861 */
			interrupts = < 0x0 0xa1 0x4 0xa0 >,
			             < 0x0 0xa2 0x4 0xa0 >,
			             < 0x0 0xa3 0x4 0xa0 >,
			             < 0x0 0xa4 0x4 0xa0 >,
			             < 0x0 0xa5 0x4 0xa0 >,
			             < 0x0 0xa6 0x4 0xa0 >,
			             < 0x0 0xa7 0x4 0xa0 >,
			             < 0x0 0xa8 0x4 0xa0 >,
			             < 0x0 0xa9 0x4 0xa0 >; /* in zephyr/dts/arm/renesas/rz/rzn/r9a07g084.dtsi:862 */
			interrupt-names = "ccmpa",
			                  "ccmpb",
			                  "cmpc",
			                  "cmpd",
			                  "cmpe",
			                  "cmpf",
			                  "ovf",
			                  "udf",
			                  "dte";            /* in zephyr/dts/arm/renesas/rz/rzn/r9a07g084.dtsi:871 */
			prescaler = < 0x1 >;                /* in zephyr/dts/arm/renesas/rz/rzn/r9a07g084.dtsi:873 */
			status = "disabled";                /* in zephyr/dts/arm/renesas/rz/rzn/r9a07g084.dtsi:874 */

			/* node '/soc/gpt5@90002500/pwm' defined in zephyr/dts/arm/renesas/rz/rzn/r9a07g084.dtsi:876 */
			pwm {
				compatible = "renesas,rz-gpt-pwm"; /* in zephyr/dts/arm/renesas/rz/rzn/r9a07g084.dtsi:877 */
				#pwm-cells = < 0x3 >;              /* in zephyr/dts/arm/renesas/rz/rzn/r9a07g084.dtsi:878 */
				status = "disabled";               /* in zephyr/dts/arm/renesas/rz/rzn/r9a07g084.dtsi:879 */
			};
		};

		/* node '/soc/gpt6@90002600' defined in zephyr/dts/arm/renesas/rz/rzn/r9a07g084.dtsi:883 */
		gpt6: gpt6@90002600 {
			compatible = "renesas,rz-gpt";      /* in zephyr/dts/arm/renesas/rz/rzn/r9a07g084.dtsi:884 */
			reg = < 0x90002600 0x100 >;         /* in zephyr/dts/arm/renesas/rz/rzn/r9a07g084.dtsi:885 */
			channel = < 0x6 >;                  /* in zephyr/dts/arm/renesas/rz/rzn/r9a07g084.dtsi:886 */
			interrupts = < 0x0 0xaa 0x4 0xa0 >,
			             < 0x0 0xab 0x4 0xa0 >,
			             < 0x0 0xac 0x4 0xa0 >,
			             < 0x0 0xad 0x4 0xa0 >,
			             < 0x0 0xae 0x4 0xa0 >,
			             < 0x0 0xaf 0x4 0xa0 >,
			             < 0x0 0xb0 0x4 0xa0 >,
			             < 0x0 0xb1 0x4 0xa0 >,
			             < 0x0 0xb2 0x4 0xa0 >; /* in zephyr/dts/arm/renesas/rz/rzn/r9a07g084.dtsi:887 */
			interrupt-names = "ccmpa",
			                  "ccmpb",
			                  "cmpc",
			                  "cmpd",
			                  "cmpe",
			                  "cmpf",
			                  "ovf",
			                  "udf",
			                  "dte";            /* in zephyr/dts/arm/renesas/rz/rzn/r9a07g084.dtsi:896 */
			prescaler = < 0x1 >;                /* in zephyr/dts/arm/renesas/rz/rzn/r9a07g084.dtsi:898 */
			status = "disabled";                /* in zephyr/dts/arm/renesas/rz/rzn/r9a07g084.dtsi:899 */

			/* node '/soc/gpt6@90002600/pwm' defined in zephyr/dts/arm/renesas/rz/rzn/r9a07g084.dtsi:901 */
			pwm {
				compatible = "renesas,rz-gpt-pwm"; /* in zephyr/dts/arm/renesas/rz/rzn/r9a07g084.dtsi:902 */
				#pwm-cells = < 0x3 >;              /* in zephyr/dts/arm/renesas/rz/rzn/r9a07g084.dtsi:903 */
				status = "disabled";               /* in zephyr/dts/arm/renesas/rz/rzn/r9a07g084.dtsi:904 */
			};
		};

		/* node '/soc/gpt7@80000000' defined in zephyr/dts/arm/renesas/rz/rzn/r9a07g084.dtsi:908 */
		gpt7: gpt7@80000000 {
			compatible = "renesas,rz-gpt";      /* in zephyr/dts/arm/renesas/rz/rzn/r9a07g084.dtsi:909 */
			reg = < 0x80000000 0x100 >;         /* in zephyr/dts/arm/renesas/rz/rzn/r9a07g084.dtsi:910 */
			channel = < 0x7 >;                  /* in zephyr/dts/arm/renesas/rz/rzn/r9a07g084.dtsi:911 */
			interrupts = < 0x0 0xb3 0x4 0xa0 >,
			             < 0x0 0xb4 0x4 0xa0 >,
			             < 0x0 0xb5 0x4 0xa0 >,
			             < 0x0 0xb6 0x4 0xa0 >,
			             < 0x0 0xb7 0x4 0xa0 >,
			             < 0x0 0xb8 0x4 0xa0 >,
			             < 0x0 0xb9 0x4 0xa0 >,
			             < 0x0 0xba 0x4 0xa0 >,
			             < 0x0 0xbb 0x4 0xa0 >; /* in zephyr/dts/arm/renesas/rz/rzn/r9a07g084.dtsi:912 */
			interrupt-names = "ccmpa",
			                  "ccmpb",
			                  "cmpc",
			                  "cmpd",
			                  "cmpe",
			                  "cmpf",
			                  "ovf",
			                  "udf",
			                  "dte";            /* in zephyr/dts/arm/renesas/rz/rzn/r9a07g084.dtsi:921 */
			prescaler = < 0x1 >;                /* in zephyr/dts/arm/renesas/rz/rzn/r9a07g084.dtsi:923 */
			status = "disabled";                /* in zephyr/dts/arm/renesas/rz/rzn/r9a07g084.dtsi:924 */

			/* node '/soc/gpt7@80000000/pwm' defined in zephyr/dts/arm/renesas/rz/rzn/r9a07g084.dtsi:926 */
			pwm {
				compatible = "renesas,rz-gpt-pwm"; /* in zephyr/dts/arm/renesas/rz/rzn/r9a07g084.dtsi:927 */
				#pwm-cells = < 0x3 >;              /* in zephyr/dts/arm/renesas/rz/rzn/r9a07g084.dtsi:928 */
				status = "disabled";               /* in zephyr/dts/arm/renesas/rz/rzn/r9a07g084.dtsi:929 */
			};
		};

		/* node '/soc/gpt8@80000100' defined in zephyr/dts/arm/renesas/rz/rzn/r9a07g084.dtsi:933 */
		gpt8: gpt8@80000100 {
			compatible = "renesas,rz-gpt";      /* in zephyr/dts/arm/renesas/rz/rzn/r9a07g084.dtsi:934 */
			reg = < 0x80000100 0x100 >;         /* in zephyr/dts/arm/renesas/rz/rzn/r9a07g084.dtsi:935 */
			channel = < 0x8 >;                  /* in zephyr/dts/arm/renesas/rz/rzn/r9a07g084.dtsi:936 */
			interrupts = < 0x0 0xbc 0x4 0xa0 >,
			             < 0x0 0xbd 0x4 0xa0 >,
			             < 0x0 0xbe 0x4 0xa0 >,
			             < 0x0 0xbf 0x4 0xa0 >,
			             < 0x0 0xc0 0x4 0xa0 >,
			             < 0x0 0xc1 0x4 0xa0 >,
			             < 0x0 0xc2 0x4 0xa0 >,
			             < 0x0 0xc3 0x4 0xa0 >,
			             < 0x0 0xc4 0x4 0xa0 >; /* in zephyr/dts/arm/renesas/rz/rzn/r9a07g084.dtsi:937 */
			interrupt-names = "ccmpa",
			                  "ccmpb",
			                  "cmpc",
			                  "cmpd",
			                  "cmpe",
			                  "cmpf",
			                  "ovf",
			                  "udf",
			                  "dte";            /* in zephyr/dts/arm/renesas/rz/rzn/r9a07g084.dtsi:946 */
			prescaler = < 0x1 >;                /* in zephyr/dts/arm/renesas/rz/rzn/r9a07g084.dtsi:948 */
			status = "disabled";                /* in zephyr/dts/arm/renesas/rz/rzn/r9a07g084.dtsi:949 */

			/* node '/soc/gpt8@80000100/pwm' defined in zephyr/dts/arm/renesas/rz/rzn/r9a07g084.dtsi:951 */
			pwm {
				compatible = "renesas,rz-gpt-pwm"; /* in zephyr/dts/arm/renesas/rz/rzn/r9a07g084.dtsi:952 */
				#pwm-cells = < 0x3 >;              /* in zephyr/dts/arm/renesas/rz/rzn/r9a07g084.dtsi:953 */
				status = "disabled";               /* in zephyr/dts/arm/renesas/rz/rzn/r9a07g084.dtsi:954 */
			};
		};

		/* node '/soc/gpt9@80000200' defined in zephyr/dts/arm/renesas/rz/rzn/r9a07g084.dtsi:958 */
		gpt9: gpt9@80000200 {
			compatible = "renesas,rz-gpt";      /* in zephyr/dts/arm/renesas/rz/rzn/r9a07g084.dtsi:959 */
			reg = < 0x80000200 0x100 >;         /* in zephyr/dts/arm/renesas/rz/rzn/r9a07g084.dtsi:960 */
			channel = < 0x9 >;                  /* in zephyr/dts/arm/renesas/rz/rzn/r9a07g084.dtsi:961 */
			interrupts = < 0x0 0xc5 0x4 0xa0 >,
			             < 0x0 0xc6 0x4 0xa0 >,
			             < 0x0 0xc7 0x4 0xa0 >,
			             < 0x0 0xc8 0x4 0xa0 >,
			             < 0x0 0xc9 0x4 0xa0 >,
			             < 0x0 0xca 0x4 0xa0 >,
			             < 0x0 0xcb 0x4 0xa0 >,
			             < 0x0 0xcc 0x4 0xa0 >,
			             < 0x0 0xcd 0x4 0xa0 >; /* in zephyr/dts/arm/renesas/rz/rzn/r9a07g084.dtsi:962 */
			interrupt-names = "ccmpa",
			                  "ccmpb",
			                  "cmpc",
			                  "cmpd",
			                  "cmpe",
			                  "cmpf",
			                  "ovf",
			                  "udf",
			                  "dte";            /* in zephyr/dts/arm/renesas/rz/rzn/r9a07g084.dtsi:971 */
			prescaler = < 0x1 >;                /* in zephyr/dts/arm/renesas/rz/rzn/r9a07g084.dtsi:973 */
			status = "disabled";                /* in zephyr/dts/arm/renesas/rz/rzn/r9a07g084.dtsi:974 */

			/* node '/soc/gpt9@80000200/pwm' defined in zephyr/dts/arm/renesas/rz/rzn/r9a07g084.dtsi:976 */
			pwm {
				compatible = "renesas,rz-gpt-pwm"; /* in zephyr/dts/arm/renesas/rz/rzn/r9a07g084.dtsi:977 */
				#pwm-cells = < 0x3 >;              /* in zephyr/dts/arm/renesas/rz/rzn/r9a07g084.dtsi:978 */
				status = "disabled";               /* in zephyr/dts/arm/renesas/rz/rzn/r9a07g084.dtsi:979 */
			};
		};

		/* node '/soc/gpt10@80000300' defined in zephyr/dts/arm/renesas/rz/rzn/r9a07g084.dtsi:983 */
		gpt10: gpt10@80000300 {
			compatible = "renesas,rz-gpt";      /* in zephyr/dts/arm/renesas/rz/rzn/r9a07g084.dtsi:984 */
			reg = < 0x80000300 0x100 >;         /* in zephyr/dts/arm/renesas/rz/rzn/r9a07g084.dtsi:985 */
			channel = < 0xa >;                  /* in zephyr/dts/arm/renesas/rz/rzn/r9a07g084.dtsi:986 */
			interrupts = < 0x0 0xce 0x4 0xa0 >,
			             < 0x0 0xcf 0x4 0xa0 >,
			             < 0x0 0xd0 0x4 0xa0 >,
			             < 0x0 0xd1 0x4 0xa0 >,
			             < 0x0 0xd2 0x4 0xa0 >,
			             < 0x0 0xd3 0x4 0xa0 >,
			             < 0x0 0xd4 0x4 0xa0 >,
			             < 0x0 0xd5 0x4 0xa0 >,
			             < 0x0 0xd6 0x4 0xa0 >; /* in zephyr/dts/arm/renesas/rz/rzn/r9a07g084.dtsi:987 */
			interrupt-names = "ccmpa",
			                  "ccmpb",
			                  "cmpc",
			                  "cmpd",
			                  "cmpe",
			                  "cmpf",
			                  "ovf",
			                  "udf",
			                  "dte";            /* in zephyr/dts/arm/renesas/rz/rzn/r9a07g084.dtsi:996 */
			prescaler = < 0x1 >;                /* in zephyr/dts/arm/renesas/rz/rzn/r9a07g084.dtsi:998 */
			status = "disabled";                /* in zephyr/dts/arm/renesas/rz/rzn/r9a07g084.dtsi:999 */

			/* node '/soc/gpt10@80000300/pwm' defined in zephyr/dts/arm/renesas/rz/rzn/r9a07g084.dtsi:1001 */
			pwm {
				compatible = "renesas,rz-gpt-pwm"; /* in zephyr/dts/arm/renesas/rz/rzn/r9a07g084.dtsi:1002 */
				#pwm-cells = < 0x3 >;              /* in zephyr/dts/arm/renesas/rz/rzn/r9a07g084.dtsi:1003 */
				status = "disabled";               /* in zephyr/dts/arm/renesas/rz/rzn/r9a07g084.dtsi:1004 */
			};
		};

		/* node '/soc/gpt11@80000400' defined in zephyr/dts/arm/renesas/rz/rzn/r9a07g084.dtsi:1008 */
		gpt11: gpt11@80000400 {
			compatible = "renesas,rz-gpt";      /* in zephyr/dts/arm/renesas/rz/rzn/r9a07g084.dtsi:1009 */
			reg = < 0x80000400 0x100 >;         /* in zephyr/dts/arm/renesas/rz/rzn/r9a07g084.dtsi:1010 */
			channel = < 0xb >;                  /* in zephyr/dts/arm/renesas/rz/rzn/r9a07g084.dtsi:1011 */
			interrupts = < 0x0 0xd7 0x4 0xa0 >,
			             < 0x0 0xd8 0x4 0xa0 >,
			             < 0x0 0xd9 0x4 0xa0 >,
			             < 0x0 0xda 0x4 0xa0 >,
			             < 0x0 0xdb 0x4 0xa0 >,
			             < 0x0 0xdc 0x4 0xa0 >,
			             < 0x0 0xdd 0x4 0xa0 >,
			             < 0x0 0xde 0x4 0xa0 >,
			             < 0x0 0xdf 0x4 0xa0 >; /* in zephyr/dts/arm/renesas/rz/rzn/r9a07g084.dtsi:1012 */
			interrupt-names = "ccmpa",
			                  "ccmpb",
			                  "cmpc",
			                  "cmpd",
			                  "cmpe",
			                  "cmpf",
			                  "ovf",
			                  "udf",
			                  "dte";            /* in zephyr/dts/arm/renesas/rz/rzn/r9a07g084.dtsi:1021 */
			prescaler = < 0x1 >;                /* in zephyr/dts/arm/renesas/rz/rzn/r9a07g084.dtsi:1023 */
			status = "disabled";                /* in zephyr/dts/arm/renesas/rz/rzn/r9a07g084.dtsi:1024 */

			/* node '/soc/gpt11@80000400/pwm' defined in zephyr/dts/arm/renesas/rz/rzn/r9a07g084.dtsi:1026 */
			pwm {
				compatible = "renesas,rz-gpt-pwm"; /* in zephyr/dts/arm/renesas/rz/rzn/r9a07g084.dtsi:1027 */
				#pwm-cells = < 0x3 >;              /* in zephyr/dts/arm/renesas/rz/rzn/r9a07g084.dtsi:1028 */
				status = "disabled";               /* in zephyr/dts/arm/renesas/rz/rzn/r9a07g084.dtsi:1029 */
			};
		};

		/* node '/soc/gpt12@80000500' defined in zephyr/dts/arm/renesas/rz/rzn/r9a07g084.dtsi:1033 */
		gpt12: gpt12@80000500 {
			compatible = "renesas,rz-gpt";      /* in zephyr/dts/arm/renesas/rz/rzn/r9a07g084.dtsi:1034 */
			reg = < 0x80000500 0x100 >;         /* in zephyr/dts/arm/renesas/rz/rzn/r9a07g084.dtsi:1035 */
			channel = < 0xc >;                  /* in zephyr/dts/arm/renesas/rz/rzn/r9a07g084.dtsi:1036 */
			interrupts = < 0x0 0xe0 0x4 0xa0 >,
			             < 0x0 0xe1 0x4 0xa0 >,
			             < 0x0 0xe2 0x4 0xa0 >,
			             < 0x0 0xe3 0x4 0xa0 >,
			             < 0x0 0xe4 0x4 0xa0 >,
			             < 0x0 0xe5 0x4 0xa0 >,
			             < 0x0 0xe6 0x4 0xa0 >,
			             < 0x0 0xe7 0x4 0xa0 >,
			             < 0x0 0xe8 0x4 0xa0 >; /* in zephyr/dts/arm/renesas/rz/rzn/r9a07g084.dtsi:1037 */
			interrupt-names = "ccmpa",
			                  "ccmpb",
			                  "cmpc",
			                  "cmpd",
			                  "cmpe",
			                  "cmpf",
			                  "ovf",
			                  "udf",
			                  "dte";            /* in zephyr/dts/arm/renesas/rz/rzn/r9a07g084.dtsi:1046 */
			prescaler = < 0x1 >;                /* in zephyr/dts/arm/renesas/rz/rzn/r9a07g084.dtsi:1048 */
			status = "disabled";                /* in zephyr/dts/arm/renesas/rz/rzn/r9a07g084.dtsi:1049 */

			/* node '/soc/gpt12@80000500/pwm' defined in zephyr/dts/arm/renesas/rz/rzn/r9a07g084.dtsi:1051 */
			pwm {
				compatible = "renesas,rz-gpt-pwm"; /* in zephyr/dts/arm/renesas/rz/rzn/r9a07g084.dtsi:1052 */
				#pwm-cells = < 0x3 >;              /* in zephyr/dts/arm/renesas/rz/rzn/r9a07g084.dtsi:1053 */
				status = "disabled";               /* in zephyr/dts/arm/renesas/rz/rzn/r9a07g084.dtsi:1054 */
			};
		};

		/* node '/soc/gpt13@80000600' defined in zephyr/dts/arm/renesas/rz/rzn/r9a07g084.dtsi:1058 */
		gpt13: gpt13@80000600 {
			compatible = "renesas,rz-gpt";      /* in zephyr/dts/arm/renesas/rz/rzn/r9a07g084.dtsi:1059 */
			reg = < 0x80000600 0x100 >;         /* in zephyr/dts/arm/renesas/rz/rzn/r9a07g084.dtsi:1060 */
			channel = < 0xd >;                  /* in zephyr/dts/arm/renesas/rz/rzn/r9a07g084.dtsi:1061 */
			interrupts = < 0x0 0xe9 0x4 0xa0 >,
			             < 0x0 0xea 0x4 0xa0 >,
			             < 0x0 0xeb 0x4 0xa0 >,
			             < 0x0 0xec 0x4 0xa0 >,
			             < 0x0 0xed 0x4 0xa0 >,
			             < 0x0 0xee 0x4 0xa0 >,
			             < 0x0 0xef 0x4 0xa0 >,
			             < 0x0 0xf0 0x4 0xa0 >,
			             < 0x0 0xf1 0x4 0xa0 >; /* in zephyr/dts/arm/renesas/rz/rzn/r9a07g084.dtsi:1062 */
			interrupt-names = "ccmpa",
			                  "ccmpb",
			                  "cmpc",
			                  "cmpd",
			                  "cmpe",
			                  "cmpf",
			                  "ovf",
			                  "udf",
			                  "dte";            /* in zephyr/dts/arm/renesas/rz/rzn/r9a07g084.dtsi:1071 */
			prescaler = < 0x1 >;                /* in zephyr/dts/arm/renesas/rz/rzn/r9a07g084.dtsi:1073 */
			status = "disabled";                /* in zephyr/dts/arm/renesas/rz/rzn/r9a07g084.dtsi:1074 */

			/* node '/soc/gpt13@80000600/pwm' defined in zephyr/dts/arm/renesas/rz/rzn/r9a07g084.dtsi:1076 */
			pwm {
				compatible = "renesas,rz-gpt-pwm"; /* in zephyr/dts/arm/renesas/rz/rzn/r9a07g084.dtsi:1077 */
				#pwm-cells = < 0x3 >;              /* in zephyr/dts/arm/renesas/rz/rzn/r9a07g084.dtsi:1078 */
				status = "disabled";               /* in zephyr/dts/arm/renesas/rz/rzn/r9a07g084.dtsi:1079 */
			};
		};

		/* node '/soc/gpt14@81000000' defined in zephyr/dts/arm/renesas/rz/rzn/r9a07g084.dtsi:1083 */
		gpt14: gpt14@81000000 {
			compatible = "renesas,rz-gpt";       /* in zephyr/dts/arm/renesas/rz/rzn/r9a07g084.dtsi:1084 */
			reg = < 0x81000000 0x100 >;          /* in zephyr/dts/arm/renesas/rz/rzn/r9a07g084.dtsi:1085 */
			channel = < 0xe >;                   /* in zephyr/dts/arm/renesas/rz/rzn/r9a07g084.dtsi:1086 */
			interrupts = < 0x0 0x18c 0x4 0xa0 >,
			             < 0x0 0x18d 0x4 0xa0 >,
			             < 0x0 0x18e 0x4 0xa0 >,
			             < 0x0 0x18f 0x4 0xa0 >,
			             < 0x0 0x190 0x4 0xa0 >,
			             < 0x0 0x191 0x4 0xa0 >,
			             < 0x0 0x192 0x4 0xa0 >,
			             < 0x0 0x193 0x4 0xa0 >; /* in zephyr/dts/arm/renesas/rz/rzn/r9a07g084.dtsi:1087 */
			interrupt-names = "ccmpa",
			                  "ccmpb",
			                  "cmpc",
			                  "cmpd",
			                  "cmpe",
			                  "cmpf",
			                  "ovf",
			                  "udf";             /* in zephyr/dts/arm/renesas/rz/rzn/r9a07g084.dtsi:1095 */
			prescaler = < 0x1 >;                 /* in zephyr/dts/arm/renesas/rz/rzn/r9a07g084.dtsi:1097 */
			status = "disabled";                 /* in zephyr/dts/arm/renesas/rz/rzn/r9a07g084.dtsi:1098 */

			/* node '/soc/gpt14@81000000/pwm' defined in zephyr/dts/arm/renesas/rz/rzn/r9a07g084.dtsi:1100 */
			pwm {
				compatible = "renesas,rz-gpt-pwm"; /* in zephyr/dts/arm/renesas/rz/rzn/r9a07g084.dtsi:1101 */
				#pwm-cells = < 0x3 >;              /* in zephyr/dts/arm/renesas/rz/rzn/r9a07g084.dtsi:1102 */
				status = "disabled";               /* in zephyr/dts/arm/renesas/rz/rzn/r9a07g084.dtsi:1103 */
			};
		};

		/* node '/soc/gpt15@81000100' defined in zephyr/dts/arm/renesas/rz/rzn/r9a07g084.dtsi:1107 */
		gpt15: gpt15@81000100 {
			compatible = "renesas,rz-gpt";       /* in zephyr/dts/arm/renesas/rz/rzn/r9a07g084.dtsi:1108 */
			reg = < 0x81000100 0x100 >;          /* in zephyr/dts/arm/renesas/rz/rzn/r9a07g084.dtsi:1109 */
			channel = < 0xf >;                   /* in zephyr/dts/arm/renesas/rz/rzn/r9a07g084.dtsi:1110 */
			interrupts = < 0x0 0x194 0x4 0xa0 >,
			             < 0x0 0x195 0x4 0xa0 >,
			             < 0x0 0x196 0x4 0xa0 >,
			             < 0x0 0x197 0x4 0xa0 >,
			             < 0x0 0x198 0x4 0xa0 >,
			             < 0x0 0x199 0x4 0xa0 >,
			             < 0x0 0x19a 0x4 0xa0 >,
			             < 0x0 0x19b 0x4 0xa0 >; /* in zephyr/dts/arm/renesas/rz/rzn/r9a07g084.dtsi:1111 */
			interrupt-names = "ccmpa",
			                  "ccmpb",
			                  "cmpc",
			                  "cmpd",
			                  "cmpe",
			                  "cmpf",
			                  "ovf",
			                  "udf";             /* in zephyr/dts/arm/renesas/rz/rzn/r9a07g084.dtsi:1119 */
			prescaler = < 0x1 >;                 /* in zephyr/dts/arm/renesas/rz/rzn/r9a07g084.dtsi:1121 */
			status = "disabled";                 /* in zephyr/dts/arm/renesas/rz/rzn/r9a07g084.dtsi:1122 */

			/* node '/soc/gpt15@81000100/pwm' defined in zephyr/dts/arm/renesas/rz/rzn/r9a07g084.dtsi:1124 */
			pwm {
				compatible = "renesas,rz-gpt-pwm"; /* in zephyr/dts/arm/renesas/rz/rzn/r9a07g084.dtsi:1125 */
				#pwm-cells = < 0x3 >;              /* in zephyr/dts/arm/renesas/rz/rzn/r9a07g084.dtsi:1126 */
				status = "disabled";               /* in zephyr/dts/arm/renesas/rz/rzn/r9a07g084.dtsi:1127 */
			};
		};

		/* node '/soc/gpt16@81000200' defined in zephyr/dts/arm/renesas/rz/rzn/r9a07g084.dtsi:1131 */
		gpt16: gpt16@81000200 {
			compatible = "renesas,rz-gpt";       /* in zephyr/dts/arm/renesas/rz/rzn/r9a07g084.dtsi:1132 */
			reg = < 0x81000200 0x100 >;          /* in zephyr/dts/arm/renesas/rz/rzn/r9a07g084.dtsi:1133 */
			channel = < 0x10 >;                  /* in zephyr/dts/arm/renesas/rz/rzn/r9a07g084.dtsi:1134 */
			interrupts = < 0x0 0x19c 0x4 0xa0 >,
			             < 0x0 0x19d 0x4 0xa0 >,
			             < 0x0 0x19e 0x4 0xa0 >,
			             < 0x0 0x19f 0x4 0xa0 >,
			             < 0x0 0x1a0 0x4 0xa0 >,
			             < 0x0 0x1a1 0x4 0xa0 >,
			             < 0x0 0x1a2 0x4 0xa0 >,
			             < 0x0 0x1a3 0x4 0xa0 >; /* in zephyr/dts/arm/renesas/rz/rzn/r9a07g084.dtsi:1135 */
			interrupt-names = "ccmpa",
			                  "ccmpb",
			                  "cmpc",
			                  "cmpd",
			                  "cmpe",
			                  "cmpf",
			                  "ovf",
			                  "udf";             /* in zephyr/dts/arm/renesas/rz/rzn/r9a07g084.dtsi:1143 */
			prescaler = < 0x1 >;                 /* in zephyr/dts/arm/renesas/rz/rzn/r9a07g084.dtsi:1145 */
			status = "disabled";                 /* in zephyr/dts/arm/renesas/rz/rzn/r9a07g084.dtsi:1146 */

			/* node '/soc/gpt16@81000200/pwm' defined in zephyr/dts/arm/renesas/rz/rzn/r9a07g084.dtsi:1148 */
			pwm {
				compatible = "renesas,rz-gpt-pwm"; /* in zephyr/dts/arm/renesas/rz/rzn/r9a07g084.dtsi:1149 */
				#pwm-cells = < 0x3 >;              /* in zephyr/dts/arm/renesas/rz/rzn/r9a07g084.dtsi:1150 */
				status = "disabled";               /* in zephyr/dts/arm/renesas/rz/rzn/r9a07g084.dtsi:1151 */
			};
		};

		/* node '/soc/gpt17@81000300' defined in zephyr/dts/arm/renesas/rz/rzn/r9a07g084.dtsi:1155 */
		gpt17: gpt17@81000300 {
			compatible = "renesas,rz-gpt";       /* in zephyr/dts/arm/renesas/rz/rzn/r9a07g084.dtsi:1156 */
			reg = < 0x81000300 0x100 >;          /* in zephyr/dts/arm/renesas/rz/rzn/r9a07g084.dtsi:1157 */
			channel = < 0x11 >;                  /* in zephyr/dts/arm/renesas/rz/rzn/r9a07g084.dtsi:1158 */
			interrupts = < 0x0 0x1a4 0x4 0xa0 >,
			             < 0x0 0x1a5 0x4 0xa0 >,
			             < 0x0 0x1a6 0x4 0xa0 >,
			             < 0x0 0x1a7 0x4 0xa0 >,
			             < 0x0 0x1a8 0x4 0xa0 >,
			             < 0x0 0x1a9 0x4 0xa0 >,
			             < 0x0 0x1aa 0x4 0xa0 >,
			             < 0x0 0x1ab 0x4 0xa0 >; /* in zephyr/dts/arm/renesas/rz/rzn/r9a07g084.dtsi:1159 */
			interrupt-names = "ccmpa",
			                  "ccmpb",
			                  "cmpc",
			                  "cmpd",
			                  "cmpe",
			                  "cmpf",
			                  "ovf",
			                  "udf";             /* in zephyr/dts/arm/renesas/rz/rzn/r9a07g084.dtsi:1167 */
			prescaler = < 0x1 >;                 /* in zephyr/dts/arm/renesas/rz/rzn/r9a07g084.dtsi:1169 */
			status = "disabled";                 /* in zephyr/dts/arm/renesas/rz/rzn/r9a07g084.dtsi:1170 */

			/* node '/soc/gpt17@81000300/pwm' defined in zephyr/dts/arm/renesas/rz/rzn/r9a07g084.dtsi:1172 */
			pwm {
				compatible = "renesas,rz-gpt-pwm"; /* in zephyr/dts/arm/renesas/rz/rzn/r9a07g084.dtsi:1173 */
				#pwm-cells = < 0x3 >;              /* in zephyr/dts/arm/renesas/rz/rzn/r9a07g084.dtsi:1174 */
				status = "disabled";               /* in zephyr/dts/arm/renesas/rz/rzn/r9a07g084.dtsi:1175 */
			};
		};

		/* node '/soc/i2c@80043000' defined in zephyr/dts/arm/renesas/rz/rzn/r9a07g084.dtsi:1179 */
		i2c0: i2c@80043000 {
			compatible = "renesas,rz-iic";       /* in zephyr/dts/arm/renesas/rz/rzn/r9a07g084.dtsi:1180 */
			channel = < 0x0 >;                   /* in zephyr/dts/arm/renesas/rz/rzn/r9a07g084.dtsi:1181 */
			clock-frequency = < 0x186a0 >;       /* in zephyr/dts/arm/renesas/rz/rzn/r9a07g084.dtsi:1182 */
			#address-cells = < 0x1 >;            /* in zephyr/dts/arm/renesas/rz/rzn/r9a07g084.dtsi:1183 */
			#size-cells = < 0x0 >;               /* in zephyr/dts/arm/renesas/rz/rzn/r9a07g084.dtsi:1184 */
			reg = < 0x80043000 0x400 >;          /* in zephyr/dts/arm/renesas/rz/rzn/r9a07g084.dtsi:1185 */
			interrupts = < 0x0 0x134 0x2 0xa0 >,
			             < 0x0 0x135 0x4 0xa0 >,
			             < 0x0 0x136 0x4 0xa0 >,
			             < 0x0 0x137 0x2 0xa0 >; /* in zephyr/dts/arm/renesas/rz/rzn/r9a07g084.dtsi:1186 */
			interrupt-names = "eri",
			                  "rxi",
			                  "txi",
			                  "tei";             /* in zephyr/dts/arm/renesas/rz/rzn/r9a07g084.dtsi:1190 */
			status = "disabled";                 /* in zephyr/dts/arm/renesas/rz/rzn/r9a07g084.dtsi:1191 */
		};

		/* node '/soc/i2c@80043400' defined in zephyr/dts/arm/renesas/rz/rzn/r9a07g084.dtsi:1194 */
		i2c1: i2c@80043400 {
			compatible = "renesas,rz-iic";       /* in zephyr/dts/arm/renesas/rz/rzn/r9a07g084.dtsi:1195 */
			channel = < 0x1 >;                   /* in zephyr/dts/arm/renesas/rz/rzn/r9a07g084.dtsi:1196 */
			clock-frequency = < 0x186a0 >;       /* in zephyr/dts/arm/renesas/rz/rzn/r9a07g084.dtsi:1197 */
			#address-cells = < 0x1 >;            /* in zephyr/dts/arm/renesas/rz/rzn/r9a07g084.dtsi:1198 */
			#size-cells = < 0x0 >;               /* in zephyr/dts/arm/renesas/rz/rzn/r9a07g084.dtsi:1199 */
			reg = < 0x80043400 0x400 >;          /* in zephyr/dts/arm/renesas/rz/rzn/r9a07g084.dtsi:1200 */
			interrupts = < 0x0 0x138 0x2 0xa0 >,
			             < 0x0 0x139 0x4 0xa0 >,
			             < 0x0 0x13a 0x4 0xa0 >,
			             < 0x0 0x13b 0x2 0xa0 >; /* in zephyr/dts/arm/renesas/rz/rzn/r9a07g084.dtsi:1201 */
			interrupt-names = "eri",
			                  "rxi",
			                  "txi",
			                  "tei";             /* in zephyr/dts/arm/renesas/rz/rzn/r9a07g084.dtsi:1205 */
			pinctrl-0 = < &i2c1_default >;       /* in zephyr/boards/renesas/rzn2l_rsk/rzn2l_rsk.dts:123 */
			pinctrl-names = "default";           /* in zephyr/boards/renesas/rzn2l_rsk/rzn2l_rsk.dts:124 */
			status = "okay";                     /* in zephyr/boards/renesas/rzn2l_rsk/rzn2l_rsk.dts:125 */
		};

		/* node '/soc/i2c@81008000' defined in zephyr/dts/arm/renesas/rz/rzn/r9a07g084.dtsi:1209 */
		i2c2: i2c@81008000 {
			compatible = "renesas,rz-iic";       /* in zephyr/dts/arm/renesas/rz/rzn/r9a07g084.dtsi:1210 */
			channel = < 0x2 >;                   /* in zephyr/dts/arm/renesas/rz/rzn/r9a07g084.dtsi:1211 */
			clock-frequency = < 0x186a0 >;       /* in zephyr/dts/arm/renesas/rz/rzn/r9a07g084.dtsi:1212 */
			#address-cells = < 0x1 >;            /* in zephyr/dts/arm/renesas/rz/rzn/r9a07g084.dtsi:1213 */
			#size-cells = < 0x0 >;               /* in zephyr/dts/arm/renesas/rz/rzn/r9a07g084.dtsi:1214 */
			reg = < 0x81008000 0x400 >;          /* in zephyr/dts/arm/renesas/rz/rzn/r9a07g084.dtsi:1215 */
			interrupts = < 0x0 0x1b7 0x2 0xa0 >,
			             < 0x0 0x1b8 0x4 0xa0 >,
			             < 0x0 0x1b9 0x4 0xa0 >,
			             < 0x0 0x1ba 0x2 0xa0 >; /* in zephyr/dts/arm/renesas/rz/rzn/r9a07g084.dtsi:1216 */
			interrupt-names = "eri",
			                  "rxi",
			                  "txi",
			                  "tei";             /* in zephyr/dts/arm/renesas/rz/rzn/r9a07g084.dtsi:1220 */
			status = "disabled";                 /* in zephyr/dts/arm/renesas/rz/rzn/r9a07g084.dtsi:1221 */
		};

		/* node '/soc/cmtw@80041000' defined in zephyr/dts/arm/renesas/rz/rzn/r9a07g084.dtsi:1224 */
		cmtw0: cmtw@80041000 {
			compatible = "renesas,rz-cmtw";     /* in zephyr/dts/arm/renesas/rz/rzn/r9a07g084.dtsi:1225 */
			reg = < 0x80041000 0x400 >;         /* in zephyr/dts/arm/renesas/rz/rzn/r9a07g084.dtsi:1226 */
			channel = < 0x0 >;                  /* in zephyr/dts/arm/renesas/rz/rzn/r9a07g084.dtsi:1227 */
			interrupts = < 0x0 0x3b 0x4 0xa0 >,
			             < 0x0 0x3c 0x4 0xa0 >,
			             < 0x0 0x3d 0x4 0xa0 >,
			             < 0x0 0x3e 0x4 0xa0 >,
			             < 0x0 0x3f 0x4 0xa0 >; /* in zephyr/dts/arm/renesas/rz/rzn/r9a07g084.dtsi:1228 */
			interrupt-names = "cmwi",
			                  "ic0i",
			                  "ic01",
			                  "oc0i",
			                  "oc1i";           /* in zephyr/dts/arm/renesas/rz/rzn/r9a07g084.dtsi:1233 */
			prescaler = < 0x8 >;                /* in zephyr/dts/arm/renesas/rz/rzn/r9a07g084.dtsi:1234 */
			status = "disabled";                /* in zephyr/dts/arm/renesas/rz/rzn/r9a07g084.dtsi:1235 */

			/* node '/soc/cmtw@80041000/counter' defined in zephyr/dts/arm/renesas/rz/rzn/r9a07g084.dtsi:1237 */
			counter {
				compatible = "renesas,rz-cmtw-counter"; /* in zephyr/dts/arm/renesas/rz/rzn/r9a07g084.dtsi:1238 */
				status = "disabled";                    /* in zephyr/dts/arm/renesas/rz/rzn/r9a07g084.dtsi:1239 */
			};
		};

		/* node '/soc/cmtw@80041400' defined in zephyr/dts/arm/renesas/rz/rzn/r9a07g084.dtsi:1243 */
		cmtw1: cmtw@80041400 {
			compatible = "renesas,rz-cmtw";     /* in zephyr/dts/arm/renesas/rz/rzn/r9a07g084.dtsi:1244 */
			reg = < 0x80041400 0x400 >;         /* in zephyr/dts/arm/renesas/rz/rzn/r9a07g084.dtsi:1245 */
			channel = < 0x1 >;                  /* in zephyr/dts/arm/renesas/rz/rzn/r9a07g084.dtsi:1246 */
			interrupts = < 0x0 0x40 0x4 0xa0 >,
			             < 0x0 0x41 0x4 0xa0 >,
			             < 0x0 0x42 0x4 0xa0 >,
			             < 0x0 0x43 0x4 0xa0 >,
			             < 0x0 0x44 0x4 0xa0 >; /* in zephyr/dts/arm/renesas/rz/rzn/r9a07g084.dtsi:1247 */
			interrupt-names = "cmwi",
			                  "ic0i",
			                  "ic01",
			                  "oc0i",
			                  "oc1i";           /* in zephyr/dts/arm/renesas/rz/rzn/r9a07g084.dtsi:1252 */
			prescaler = < 0x8 >;                /* in zephyr/dts/arm/renesas/rz/rzn/r9a07g084.dtsi:1253 */
			status = "disabled";                /* in zephyr/dts/arm/renesas/rz/rzn/r9a07g084.dtsi:1254 */

			/* node '/soc/cmtw@80041400/counter' defined in zephyr/dts/arm/renesas/rz/rzn/r9a07g084.dtsi:1256 */
			counter {
				compatible = "renesas,rz-cmtw-counter"; /* in zephyr/dts/arm/renesas/rz/rzn/r9a07g084.dtsi:1257 */
				status = "disabled";                    /* in zephyr/dts/arm/renesas/rz/rzn/r9a07g084.dtsi:1258 */
			};
		};

		/* node '/soc/dma@80080000' defined in zephyr/dts/arm/renesas/rz/rzn/r9a07g084.dtsi:1262 */
		dma0: dma@80080000 {
			compatible = "renesas,rz-dmac";     /* in zephyr/dts/arm/renesas/rz/rzn/r9a07g084.dtsi:1263 */
			reg = < 0x80080000 0x1000 >;        /* in zephyr/dts/arm/renesas/rz/rzn/r9a07g084.dtsi:1264 */
			interrupts = < 0x0 0x15 0x2 0xa0 >,
			             < 0x0 0x16 0x2 0xa0 >,
			             < 0x0 0x17 0x2 0xa0 >,
			             < 0x0 0x18 0x2 0xa0 >,
			             < 0x0 0x19 0x2 0xa0 >,
			             < 0x0 0x1a 0x2 0xa0 >,
			             < 0x0 0x1b 0x2 0xa0 >,
			             < 0x0 0x1c 0x2 0xa0 >; /* in zephyr/dts/arm/renesas/rz/rzn/r9a07g084.dtsi:1265 */
			interrupt-names = "ch0",
			                  "ch1",
			                  "ch2",
			                  "ch3",
			                  "ch4",
			                  "ch5",
			                  "ch6",
			                  "ch7";            /* in zephyr/dts/arm/renesas/rz/rzn/r9a07g084.dtsi:1273 */
			dma-unit = < 0x0 >;                 /* in zephyr/dts/arm/renesas/rz/rzn/r9a07g084.dtsi:1275 */
			dma-channels = < 0x8 >;             /* in zephyr/dts/arm/renesas/rz/rzn/r9a07g084.dtsi:1276 */
			#dma-cells = < 0x2 >;               /* in zephyr/dts/arm/renesas/rz/rzn/r9a07g084.dtsi:1277 */
			status = "disabled";                /* in zephyr/dts/arm/renesas/rz/rzn/r9a07g084.dtsi:1278 */
		};

		/* node '/soc/dma@80081000' defined in zephyr/dts/arm/renesas/rz/rzn/r9a07g084.dtsi:1281 */
		dma1: dma@80081000 {
			compatible = "renesas,rz-dmac";     /* in zephyr/dts/arm/renesas/rz/rzn/r9a07g084.dtsi:1282 */
			reg = < 0x80081000 0x1000 >;        /* in zephyr/dts/arm/renesas/rz/rzn/r9a07g084.dtsi:1283 */
			interrupts = < 0x0 0x25 0x2 0xa0 >,
			             < 0x0 0x26 0x2 0xa0 >,
			             < 0x0 0x27 0x2 0xa0 >,
			             < 0x0 0x28 0x2 0xa0 >,
			             < 0x0 0x29 0x2 0xa0 >,
			             < 0x0 0x2a 0x2 0xa0 >,
			             < 0x0 0x2b 0x2 0xa0 >,
			             < 0x0 0x2c 0x2 0xa0 >; /* in zephyr/dts/arm/renesas/rz/rzn/r9a07g084.dtsi:1284 */
			interrupt-names = "ch0",
			                  "ch1",
			                  "ch2",
			                  "ch3",
			                  "ch4",
			                  "ch5",
			                  "ch6",
			                  "ch7";            /* in zephyr/dts/arm/renesas/rz/rzn/r9a07g084.dtsi:1292 */
			dma-unit = < 0x1 >;                 /* in zephyr/dts/arm/renesas/rz/rzn/r9a07g084.dtsi:1294 */
			dma-channels = < 0x8 >;             /* in zephyr/dts/arm/renesas/rz/rzn/r9a07g084.dtsi:1295 */
			#dma-cells = < 0x2 >;               /* in zephyr/dts/arm/renesas/rz/rzn/r9a07g084.dtsi:1296 */
			status = "disabled";                /* in zephyr/dts/arm/renesas/rz/rzn/r9a07g084.dtsi:1297 */
		};

		/* node '/soc/spi@80003000' defined in zephyr/dts/arm/renesas/rz/rzn/r9a07g084.dtsi:1300 */
		spi0: spi@80003000 {
			compatible = "renesas,rz-spi";       /* in zephyr/dts/arm/renesas/rz/rzn/r9a07g084.dtsi:1301 */
			reg = < 0x80003000 0x74 >;           /* in zephyr/dts/arm/renesas/rz/rzn/r9a07g084.dtsi:1302 */
			interrupts = < 0x0 0x144 0x4 0xa0 >,
			             < 0x0 0x145 0x4 0xa0 >,
			             < 0x0 0x146 0x2 0xa0 >,
			             < 0x0 0x147 0x2 0xa0 >,
			             < 0x0 0x148 0x4 0xa0 >; /* in zephyr/dts/arm/renesas/rz/rzn/r9a07g084.dtsi:1303 */
			interrupt-names = "rxi",
			                  "txi",
			                  "idle",
			                  "eri",
			                  "tei";             /* in zephyr/dts/arm/renesas/rz/rzn/r9a07g084.dtsi:1308 */
			channel = < 0x0 >;                   /* in zephyr/dts/arm/renesas/rz/rzn/r9a07g084.dtsi:1309 */
			clk-src = < 0x0 >;                   /* in zephyr/dts/arm/renesas/rz/rzn/r9a07g084.dtsi:1310 */
			#address-cells = < 0x1 >;            /* in zephyr/dts/arm/renesas/rz/rzn/r9a07g084.dtsi:1311 */
			#size-cells = < 0x0 >;               /* in zephyr/dts/arm/renesas/rz/rzn/r9a07g084.dtsi:1312 */
			status = "disabled";                 /* in zephyr/dts/arm/renesas/rz/rzn/r9a07g084.dtsi:1313 */
		};

		/* node '/soc/spi@80003400' defined in zephyr/dts/arm/renesas/rz/rzn/r9a07g084.dtsi:1316 */
		spi1: spi@80003400 {
			compatible = "renesas,rz-spi";       /* in zephyr/dts/arm/renesas/rz/rzn/r9a07g084.dtsi:1317 */
			reg = < 0x80003400 0x74 >;           /* in zephyr/dts/arm/renesas/rz/rzn/r9a07g084.dtsi:1318 */
			interrupts = < 0x0 0x149 0x4 0xa0 >,
			             < 0x0 0x14a 0x4 0xa0 >,
			             < 0x0 0x14b 0x2 0xa0 >,
			             < 0x0 0x14c 0x2 0xa0 >,
			             < 0x0 0x14d 0x4 0xa0 >; /* in zephyr/dts/arm/renesas/rz/rzn/r9a07g084.dtsi:1319 */
			interrupt-names = "rxi",
			                  "txi",
			                  "idle",
			                  "eri",
			                  "tei";             /* in zephyr/dts/arm/renesas/rz/rzn/r9a07g084.dtsi:1324 */
			channel = < 0x1 >;                   /* in zephyr/dts/arm/renesas/rz/rzn/r9a07g084.dtsi:1325 */
			clk-src = < 0x1 >;                   /* in zephyr/dts/arm/renesas/rz/rzn/r9a07g084.dtsi:1326 */
			#address-cells = < 0x1 >;            /* in zephyr/dts/arm/renesas/rz/rzn/r9a07g084.dtsi:1327 */
			#size-cells = < 0x0 >;               /* in zephyr/dts/arm/renesas/rz/rzn/r9a07g084.dtsi:1328 */
			status = "disabled";                 /* in zephyr/dts/arm/renesas/rz/rzn/r9a07g084.dtsi:1329 */
		};

		/* node '/soc/spi@80003800' defined in zephyr/dts/arm/renesas/rz/rzn/r9a07g084.dtsi:1332 */
		spi2: spi@80003800 {
			compatible = "renesas,rz-spi";       /* in zephyr/dts/arm/renesas/rz/rzn/r9a07g084.dtsi:1333 */
			reg = < 0x80003800 0x74 >;           /* in zephyr/dts/arm/renesas/rz/rzn/r9a07g084.dtsi:1334 */
			interrupts = < 0x0 0x14e 0x4 0xa0 >,
			             < 0x0 0x14f 0x4 0xa0 >,
			             < 0x0 0x150 0x2 0xa0 >,
			             < 0x0 0x151 0x2 0xa0 >,
			             < 0x0 0x152 0x4 0xa0 >; /* in zephyr/dts/arm/renesas/rz/rzn/r9a07g084.dtsi:1335 */
			interrupt-names = "rxi",
			                  "txi",
			                  "idle",
			                  "eri",
			                  "tei";             /* in zephyr/dts/arm/renesas/rz/rzn/r9a07g084.dtsi:1340 */
			channel = < 0x2 >;                   /* in zephyr/dts/arm/renesas/rz/rzn/r9a07g084.dtsi:1341 */
			clk-src = < 0x2 >;                   /* in zephyr/dts/arm/renesas/rz/rzn/r9a07g084.dtsi:1342 */
			#address-cells = < 0x1 >;            /* in zephyr/dts/arm/renesas/rz/rzn/r9a07g084.dtsi:1343 */
			#size-cells = < 0x0 >;               /* in zephyr/dts/arm/renesas/rz/rzn/r9a07g084.dtsi:1344 */
			pinctrl-0 = < &spi2_pins >;          /* in zephyr/boards/renesas/rzn2l_rsk/rzn2l_rsk.dts:129 */
			pinctrl-names = "default";           /* in zephyr/boards/renesas/rzn2l_rsk/rzn2l_rsk.dts:130 */
			status = "okay";                     /* in zephyr/boards/renesas/rzn2l_rsk/rzn2l_rsk.dts:131 */
		};

		/* node '/soc/spi@81002000' defined in zephyr/dts/arm/renesas/rz/rzn/r9a07g084.dtsi:1348 */
		spi3: spi@81002000 {
			compatible = "renesas,rz-spi";       /* in zephyr/dts/arm/renesas/rz/rzn/r9a07g084.dtsi:1349 */
			reg = < 0x81002000 0x74 >;           /* in zephyr/dts/arm/renesas/rz/rzn/r9a07g084.dtsi:1350 */
			interrupts = < 0x0 0x1bb 0x4 0xa0 >,
			             < 0x0 0x1bc 0x4 0xa0 >,
			             < 0x0 0x1bd 0x2 0xa0 >,
			             < 0x0 0x1be 0x2 0xa0 >,
			             < 0x0 0x1bf 0x4 0xa0 >; /* in zephyr/dts/arm/renesas/rz/rzn/r9a07g084.dtsi:1351 */
			interrupt-names = "rxi",
			                  "txi",
			                  "idle",
			                  "eri",
			                  "tei";             /* in zephyr/dts/arm/renesas/rz/rzn/r9a07g084.dtsi:1356 */
			channel = < 0x3 >;                   /* in zephyr/dts/arm/renesas/rz/rzn/r9a07g084.dtsi:1357 */
			clk-src = < 0x3 >;                   /* in zephyr/dts/arm/renesas/rz/rzn/r9a07g084.dtsi:1358 */
			#address-cells = < 0x1 >;            /* in zephyr/dts/arm/renesas/rz/rzn/r9a07g084.dtsi:1359 */
			#size-cells = < 0x0 >;               /* in zephyr/dts/arm/renesas/rz/rzn/r9a07g084.dtsi:1360 */
			status = "disabled";                 /* in zephyr/dts/arm/renesas/rz/rzn/r9a07g084.dtsi:1361 */
		};

		/* node '/soc/watchdog@80042000' defined in zephyr/dts/arm/renesas/rz/rzn/r9a07g084.dtsi:1364 */
		wdt0: watchdog@80042000 {
			compatible = "renesas,rz-wdt";       /* in zephyr/dts/arm/renesas/rz/rzn/r9a07g084.dtsi:1365 */
			reg = < 0x80042000 0x1000 >;         /* in zephyr/dts/arm/renesas/rz/rzn/r9a07g084.dtsi:1366 */
			clock-freq = < 0x2faf080 >;          /* in zephyr/dts/arm/renesas/rz/rzn/r9a07g084.dtsi:1367 */
			interrupts = < 0x0 0x184 0x4 0xa0 >; /* in zephyr/dts/arm/renesas/rz/rzn/r9a07g084.dtsi:1368 */
			status = "okay";                     /* in zephyr/boards/renesas/rzn2l_rsk/rzn2l_rsk.dts:135 */
		};

		/* node '/soc/xspi@80220000' defined in zephyr/dts/arm/renesas/rz/rzn/r9a07g084.dtsi:1372 */
		xspi0: xspi@80220000 {
			compatible = "renesas,rz-xspi";      /* in zephyr/dts/arm/renesas/rz/rzn/r9a07g084.dtsi:1373 */
			reg = < 0x80220000 0x1000 >;         /* in zephyr/dts/arm/renesas/rz/rzn/r9a07g084.dtsi:1374 */
			interrupts = < 0x0 0x153 0x2 0xa0 >,
			             < 0x0 0x154 0x2 0xa0 >; /* in zephyr/dts/arm/renesas/rz/rzn/r9a07g084.dtsi:1375 */
			#address-cells = < 0x1 >;            /* in zephyr/dts/arm/renesas/rz/rzn/r9a07g084.dtsi:1377 */
			#size-cells = < 0x1 >;               /* in zephyr/dts/arm/renesas/rz/rzn/r9a07g084.dtsi:1378 */
			pinctrl-0 = < &xspi0_default >;      /* in zephyr/boards/renesas/rzn2l_rsk/rzn2l_rsk.dts:139 */
			pinctrl-names = "default";           /* in zephyr/boards/renesas/rzn2l_rsk/rzn2l_rsk.dts:140 */
			status = "okay";                     /* in zephyr/boards/renesas/rzn2l_rsk/rzn2l_rsk.dts:141 */

			/* node '/soc/xspi@80220000/qspi-nor-flash@60000000' defined in zephyr/boards/renesas/rzn2l_rsk/rzn2l_rsk.dts:143 */
			mx25u51245g: qspi-nor-flash@60000000 {
				compatible = "renesas,rz-qspi-xspi"; /* in zephyr/boards/renesas/rzn2l_rsk/rzn2l_rsk.dts:144 */
				reg = < 0x60000000 0x4000000 >;      /* in zephyr/boards/renesas/rzn2l_rsk/rzn2l_rsk.dts:145 */
				write-block-size = < 0x1 >;          /* in zephyr/boards/renesas/rzn2l_rsk/rzn2l_rsk.dts:146 */
				erase-block-size = < 0x1000 >;       /* in zephyr/boards/renesas/rzn2l_rsk/rzn2l_rsk.dts:147 */
				status = "okay";                     /* in zephyr/boards/renesas/rzn2l_rsk/rzn2l_rsk.dts:148 */
			};
		};

		/* node '/soc/xspi@80221000' defined in zephyr/dts/arm/renesas/rz/rzn/r9a07g084.dtsi:1382 */
		xspi1: xspi@80221000 {
			compatible = "renesas,rz-xspi";      /* in zephyr/dts/arm/renesas/rz/rzn/r9a07g084.dtsi:1383 */
			reg = < 0x80221000 0x1000 >;         /* in zephyr/dts/arm/renesas/rz/rzn/r9a07g084.dtsi:1384 */
			interrupts = < 0x0 0x155 0x2 0xa0 >,
			             < 0x0 0x156 0x2 0xa0 >; /* in zephyr/dts/arm/renesas/rz/rzn/r9a07g084.dtsi:1385 */
			#address-cells = < 0x1 >;            /* in zephyr/dts/arm/renesas/rz/rzn/r9a07g084.dtsi:1387 */
			#size-cells = < 0x1 >;               /* in zephyr/dts/arm/renesas/rz/rzn/r9a07g084.dtsi:1388 */
			status = "disabled";                 /* in zephyr/dts/arm/renesas/rz/rzn/r9a07g084.dtsi:1389 */
		};
	};

	/* node '/cpus' defined in zephyr/dts/arm/renesas/rz/rzn/r9a07g084.dtsi:20 */
	cpus {
		#address-cells = < 0x1 >; /* in zephyr/dts/arm/renesas/rz/rzn/r9a07g084.dtsi:21 */
		#size-cells = < 0x0 >;    /* in zephyr/dts/arm/renesas/rz/rzn/r9a07g084.dtsi:22 */

		/* node '/cpus/cpu@0' defined in zephyr/dts/arm/renesas/rz/rzn/r9a07g084.dtsi:24 */
		cpu@0 {
			device_type = "cpu";           /* in zephyr/dts/arm/renesas/rz/rzn/r9a07g084.dtsi:25 */
			compatible = "arm,cortex-r52"; /* in zephyr/dts/arm/renesas/rz/rzn/r9a07g084.dtsi:26 */
			reg = < 0x0 >;                 /* in zephyr/dts/arm/renesas/rz/rzn/r9a07g084.dtsi:27 */
		};
	};

	/* node '/timer' defined in zephyr/dts/arm/renesas/rz/rzn/r9a07g084.dtsi:31 */
	arch_timer: timer {
		compatible = "arm,armv8-timer";    /* in zephyr/dts/arm/renesas/rz/rzn/r9a07g084.dtsi:32 */
		interrupts = < 0x1 0xd 0x2 0xa0 >,
		             < 0x1 0xe 0x2 0xa0 >,
		             < 0x1 0xb 0x2 0xa0 >,
		             < 0x1 0xa 0x2 0xa0 >; /* in zephyr/dts/arm/renesas/rz/rzn/r9a07g084.dtsi:33 */
		interrupt-parent = < &gic >;       /* in zephyr/dts/arm/renesas/rz/rzn/r9a07g084.dtsi:37 */
	};

	/* node '/osc' defined in zephyr/dts/arm/renesas/rz/rzn/r9a07g084.dtsi:40 */
	osc: osc {
		compatible = "fixed-clock";      /* in zephyr/dts/arm/renesas/rz/rzn/r9a07g084.dtsi:41 */
		clock-frequency = < 0x17d7840 >; /* in zephyr/dts/arm/renesas/rz/rzn/r9a07g084.dtsi:42 */
		#clock-cells = < 0x0 >;          /* in zephyr/dts/arm/renesas/rz/rzn/r9a07g084.dtsi:43 */
		phandle = < 0x2 >;               /* in zephyr/dts/arm/renesas/rz/rzn/r9a07g084.dtsi:105 */
	};

	/* node '/leds' defined in zephyr/boards/renesas/rzn2l_rsk/rzn2l_rsk.dts:30 */
	leds {
		compatible = "gpio-leds"; /* in zephyr/boards/renesas/rzn2l_rsk/rzn2l_rsk.dts:31 */

		/* node '/leds/led0' defined in zephyr/boards/renesas/rzn2l_rsk/rzn2l_rsk.dts:33 */
		led0: led0 {
			gpios = < &gpio18 0x2 0x0 >; /* in zephyr/boards/renesas/rzn2l_rsk/rzn2l_rsk.dts:34 */
			label = "led0";              /* in zephyr/boards/renesas/rzn2l_rsk/rzn2l_rsk.dts:35 */
		};

		/* node '/leds/led1' defined in zephyr/boards/renesas/rzn2l_rsk/rzn2l_rsk.dts:38 */
		led1: led1 {
			gpios = < &gpio22 0x3 0x0 >; /* in zephyr/boards/renesas/rzn2l_rsk/rzn2l_rsk.dts:39 */
			label = "led1";              /* in zephyr/boards/renesas/rzn2l_rsk/rzn2l_rsk.dts:40 */
		};

		/* node '/leds/led2' defined in zephyr/boards/renesas/rzn2l_rsk/rzn2l_rsk.dts:43 */
		led2: led2 {
			gpios = < &gpio4 0x1 0x0 >; /* in zephyr/boards/renesas/rzn2l_rsk/rzn2l_rsk.dts:44 */
			label = "led2";             /* in zephyr/boards/renesas/rzn2l_rsk/rzn2l_rsk.dts:45 */
		};

		/* node '/leds/led3' defined in zephyr/boards/renesas/rzn2l_rsk/rzn2l_rsk.dts:48 */
		led3: led3 {
			gpios = < &gpio17 0x3 0x0 >; /* in zephyr/boards/renesas/rzn2l_rsk/rzn2l_rsk.dts:49 */
			label = "led3";              /* in zephyr/boards/renesas/rzn2l_rsk/rzn2l_rsk.dts:50 */
		};
	};

	/* node '/gpio_keys' defined in zephyr/boards/renesas/rzn2l_rsk/rzn2l_rsk.dts:54 */
	gpio_keys {
		compatible = "gpio-keys"; /* in zephyr/boards/renesas/rzn2l_rsk/rzn2l_rsk.dts:55 */

		/* node '/gpio_keys/sw1' defined in zephyr/boards/renesas/rzn2l_rsk/rzn2l_rsk.dts:57 */
		sw1: sw1 {
			label = "sw1";               /* in zephyr/boards/renesas/rzn2l_rsk/rzn2l_rsk.dts:58 */
			gpios = < &gpio16 0x3 0x0 >; /* in zephyr/boards/renesas/rzn2l_rsk/rzn2l_rsk.dts:59 */
			zephyr,code = < 0xb >;       /* in zephyr/boards/renesas/rzn2l_rsk/rzn2l_rsk.dts:60 */
		};

		/* node '/gpio_keys/sw2' defined in zephyr/boards/renesas/rzn2l_rsk/rzn2l_rsk.dts:63 */
		sw2: sw2 {
			label = "sw2";              /* in zephyr/boards/renesas/rzn2l_rsk/rzn2l_rsk.dts:64 */
			gpios = < &gpio5 0x4 0x0 >; /* in zephyr/boards/renesas/rzn2l_rsk/rzn2l_rsk.dts:65 */
			zephyr,code = < 0x2 >;      /* in zephyr/boards/renesas/rzn2l_rsk/rzn2l_rsk.dts:66 */
		};
	};
};
